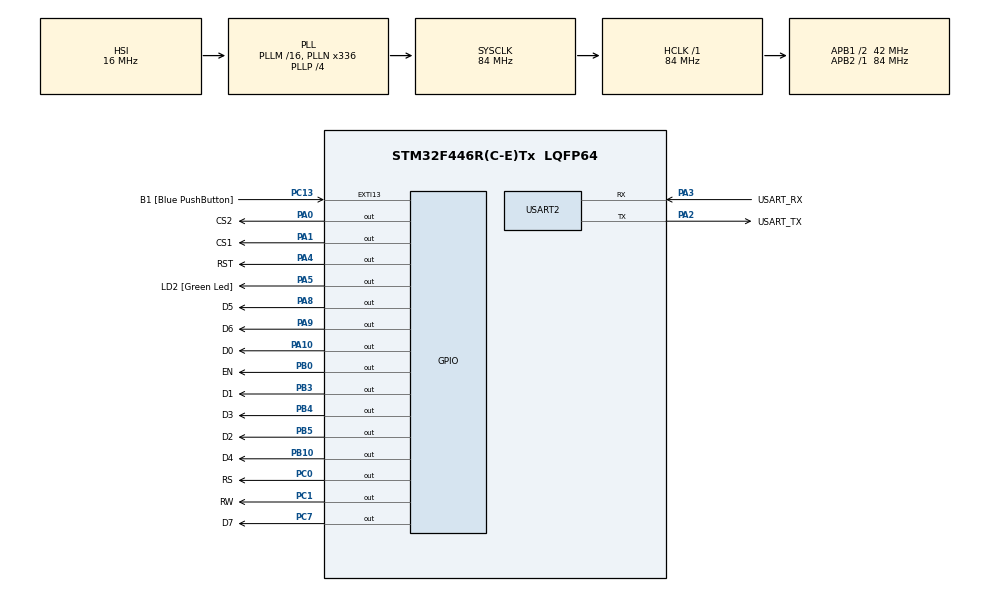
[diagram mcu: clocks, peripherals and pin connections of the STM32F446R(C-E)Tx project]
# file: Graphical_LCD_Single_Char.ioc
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Mcu.Family=STM32F4
Mcu.Name=STM32F446R(C-E)Tx
Mcu.Package=LQFP64
NVIC.PriorityGroup=NVIC_PRIORITYGROUP_0
PA0-WKUP.GPIO_Label=CS2
PA0-WKUP.Signal=GPIO_Output
PA1.GPIO_Label=CS1
PA1.Signal=GPIO_Output
PA10.GPIO_Label=D0
PA10.Signal=GPIO_Output
PA13.GPIO_Label=TMS
PA13.Mode=Serial_Wire
PA13.Signal=SYS_JTMS-SWDIO
PA14.GPIO_Label=TCK
PA14.Mode=Serial_Wire
PA14.Signal=SYS_JTCK-SWCLK
PA2.GPIO_Label=USART_TX
PA2.Mode=Asynchronous
PA2.Signal=USART2_TX
PA3.GPIO_Label=USART_RX
PA3.Mode=Asynchronous
PA3.Signal=USART2_RX
PA4.GPIO_Label=RST
PA4.Signal=GPIO_Output
PA5.GPIO_Label=LD2 [Green Led]
PA5.Signal=GPIO_Output
PA8.GPIO_Label=D5
PA8.Signal=GPIO_Output
PA9.GPIO_Label=D6
PA9.Signal=GPIO_Output
PB0.GPIO_Label=EN
PB0.Signal=GPIO_Output
PB10.GPIO_Label=D4
PB10.Signal=GPIO_Output
PB3.GPIO_Label=D1
PB3.Signal=GPIO_Output
PB4.GPIO_Label=D3
PB4.Signal=GPIO_Output
PB5.GPIO_Label=D2
PB5.Signal=GPIO_Output
PC0.GPIO_Label=RS
PC0.Signal=GPIO_Output
PC1.GPIO_Label=RW
PC1.Signal=GPIO_Output
PC13.GPIO_Label=B1 [Blue PushButton]
PC13.GPIO_ModeDefaultEXTI=GPIO_MODE_IT_FALLING
PC13.Signal=GPXTI13
PC14-OSC32_IN.Mode=LSE-External-Oscillator
PC14-OSC32_IN.Signal=RCC_OSC32_IN
PC15-OSC32_OUT.Mode=LSE-External-Oscillator
PC15-OSC32_OUT.Signal=RCC_OSC32_OUT
PC7.GPIO_Label=D7
PC7.Signal=GPIO_Output
PH0-OSC_IN.Mode=HSE-External-Oscillator
PH0-OSC_IN.Signal=RCC_OSC_IN
PH1-OSC_OUT.Mode=HSE-External-Oscillator
PH1-OSC_OUT.Signal=RCC_OSC_OUT
ProjectManager.HeapSize=0x200
ProjectManager.StackSize=0x400
ProjectManager.TargetToolchain=STM32CubeIDE
RCC.48MHZClocksFreq_Value=84000000
RCC.AHBFreq_Value=84000000
RCC.APB1CLKDivider=RCC_HCLK_DIV2
RCC.APB1Freq_Value=42000000
RCC.APB1TimFreq_Value=84000000
RCC.APB2Freq_Value=84000000
RCC.APB2TimFreq_Value=84000000
RCC.CortexFreq_Value=84000000
RCC.FLatency-AdvancedSettings=FLASH_LATENCY_2
RCC.HCLKFreq_Value=84000000
RCC.HSE_VALUE=8000000
RCC.HSI_VALUE=16000000
RCC.PLLN=336
RCC.PLLP=RCC_PLLP_DIV4
RCC.SYSCLKFreq_VALUE=84000000
RCC.SYSCLKSource=RCC_SYSCLKSOURCE_PLLCLK
RCC.USBFreq_Value=168000000
RCC.VCOOutputFreq_Value=336000000
USART2.VirtualMode=VM_ASYNC
board=NUCLEO-F446RE

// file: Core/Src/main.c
/* USER CODE BEGIN Header */
/**
  ******************************************************************************
  * @file           : main.c
  * @brief          : Main program body
  ******************************************************************************
  * @attention
  *
  * Copyright (c) 2023 STMicroelectronics.
  * All rights reserved.
  *
  * This software is licensed under terms that can be found in the LICENSE file
  * in the root directory of this software component.
  * If no LICENSE file comes with this software, it is provided AS-IS.
  *
  ******************************************************************************
  */
/* USER CODE END Header */
#include "main.h"

/* USER CODE BEGIN Includes */
#include <stdio.h>
#include <string.h>
#include "GLCD_FONT.h"
/* USER CODE END Includes */

/* USER CODE BEGIN PTD */

typedef union{

	struct {

		uint8_t b0:1;
		uint8_t b1:1;
		uint8_t b2:1;
		uint8_t b3:1;
		uint8_t b4:1;
		uint8_t b5:1;
		uint8_t b6:1;
		uint8_t b7:1;
	};

	uint8_t x;
}Typedef_PinConfig;
/* USER CODE END PTD */

UART_HandleTypeDef huart2;

/* USER CODE BEGIN PV */

char data1[] = {0x7F, 0x08, 0x08, 0x08, 0x7F};
char data2[] = {0x7F, 0x49, 0x49, 0x49, 0x41};
char data3[] = {0x7F, 0x40, 0x40, 0x40, 0x40};
char data4[] = {0x7F, 0x40, 0x40, 0x40, 0x40};
char data5[] = {0x3E, 0x41, 0x41, 0x41, 0x3E};

//const char dog[] = {
//		0xff, 0xff, 0xff, 0xff, 0xff, 0xff, 0xff, 0xff, 0xff, 0xff, 0xff, 0xf8, 0x3f, 0xff, 0xff, 0xff,
//		0xff, 0xff, 0xff, 0xff, 0xff, 0xff, 0xff, 0xff, 0xff, 0xff, 0xff, 0xff, 0xff, 0xff, 0xff, 0xff,
//		0xff, 0xff, 0xff, 0xff, 0xff, 0xf0, 0xff, 0xff, 0xff, 0xff, 0xff, 0xff, 0xff, 0xff, 0xff, 0xff,
//		0xff, 0xfc, 0x1f, 0xff, 0xff, 0xff, 0xff, 0xff, 0xff, 0xff, 0xff, 0xff, 0xff, 0xff, 0xff, 0xff,
//		0xff, 0xff, 0xff, 0xff, 0xff, 0xff, 0xff, 0xff, 0xff, 0xff, 0xff, 0xf0, 0xff, 0xff, 0xff, 0xff,
//		0xff, 0xff, 0xff, 0xff, 0xff, 0xff, 0xff, 0xff, 0x1f, 0xff, 0xff, 0xff, 0xff, 0xff, 0xff, 0xff,
//		0xff, 0xff, 0xff, 0xff, 0xff, 0xff, 0xff, 0xff, 0xff, 0xff, 0xff, 0xff, 0xff, 0xff, 0xff, 0xff,
//		0xff, 0xf0, 0xff, 0xff, 0xff, 0xff, 0xff, 0xff, 0xff, 0xff, 0xff, 0xff, 0xff, 0xff, 0xff, 0xff,
//		0xff, 0xff, 0xff, 0xff, 0xff, 0xff, 0xff, 0xff, 0xff, 0xff, 0xff, 0xff, 0xff, 0xff, 0xff, 0xff,
//		0xff, 0xff, 0xff, 0xff, 0xff, 0xff, 0xff, 0xf0, 0xff, 0xff, 0xff, 0xff, 0xff, 0xff, 0xff, 0xff,
//		0xff, 0xff, 0xff, 0xff, 0x9f, 0xff, 0xff, 0xff, 0xff, 0xff, 0xff, 0xff, 0xff, 0xff, 0xff, 0xff,
//		0xff, 0xff, 0xff, 0xff, 0xff, 0xff, 0xff, 0xff, 0xff, 0xff, 0xff, 0xff, 0xff, 0xf0, 0xff, 0xff,
//		0xff, 0xff, 0xff, 0xff, 0xff, 0xff, 0xff, 0xff, 0xfe, 0x7f, 0xcf, 0xff, 0xff, 0xff, 0xff, 0xff,
//		0xff, 0xff, 0xff, 0xff, 0xff, 0xff, 0xff, 0xff, 0xff, 0xff, 0xff, 0xff, 0xff, 0xff, 0xff, 0xff,
//		0xff, 0xff, 0xff, 0xf0, 0xff, 0xff, 0xff, 0xff, 0xff, 0xff, 0xff, 0xff, 0xff, 0xff, 0xfe, 0x1f,
//		0xe7, 0xff, 0xff, 0xff, 0xff, 0xff, 0xff, 0xff, 0xff, 0xff, 0xff, 0xff, 0xff, 0xff, 0xff, 0xff,
//		0xff, 0xff, 0xff, 0xff, 0xff, 0xff, 0xff, 0xff, 0xff, 0xf0, 0xff, 0xff, 0xff, 0xff, 0xff, 0xff,
//		0xff, 0xff, 0xff, 0xff, 0xfe, 0x0f, 0xff, 0xff, 0xff, 0xff, 0xff, 0xff, 0xff, 0xff, 0xff, 0xff,
//		0xff, 0xff, 0xff, 0xff, 0xff, 0xff, 0xff, 0xff, 0xff, 0xff, 0xff, 0xff, 0xff, 0xff, 0xff, 0xf0,
//		0xff, 0xff, 0xff, 0xff, 0xff, 0xff, 0xff, 0xff, 0xff, 0xff, 0xfe, 0x07, 0xff, 0xff, 0xff, 0xff,
//		0xff, 0xff, 0xff, 0xff, 0xff, 0xff, 0xff, 0xff, 0xff, 0xf7, 0xff, 0xff, 0xff, 0xff, 0xff, 0xff,
//		0xff, 0xff, 0xff, 0xff, 0xff, 0xf0, 0xff, 0xff, 0xff, 0xff, 0xff, 0xff, 0xff, 0xff, 0xff, 0xff,
//		0xff, 0x83, 0xff, 0xff, 0xff, 0xff, 0xff, 0xff, 0xff, 0xff, 0xff, 0xff, 0xff, 0xff, 0xff, 0xe2,
//		0xff, 0xff, 0xff, 0xff, 0xff, 0xff, 0xff, 0xff, 0xff, 0xff, 0xff, 0xf0, 0xff, 0xff, 0xff, 0xff,
//		0xff, 0xff, 0xff, 0xff, 0xff, 0xff, 0xff, 0x01, 0xff, 0xff, 0xff, 0xff, 0xff, 0xff, 0xff, 0xff,
//		0xff, 0xff, 0xff, 0xff, 0xff, 0xe0, 0xff, 0xff, 0xff, 0xff, 0xff, 0xff, 0xff, 0xff, 0xff, 0xff,
//		0xff, 0xf0, 0xff, 0xff, 0xff, 0xff, 0xff, 0xff, 0xff, 0xff, 0xff, 0xff, 0xfc, 0x00, 0xff, 0xff,
//		0xff, 0xff, 0xff, 0xff, 0xff, 0xff, 0xff, 0xff, 0xff, 0xff, 0xfe, 0xc0, 0xff, 0xff, 0xff, 0xff,
//		0xff, 0xff, 0xff, 0xff, 0xff, 0xff, 0xff, 0xf0, 0xff, 0xff, 0xff, 0xff, 0xff, 0xff, 0xff, 0xff,
//		0xff, 0xff, 0xfc, 0x00, 0x7f, 0xff, 0xff, 0xff, 0xff, 0xff, 0xff, 0xff, 0xff, 0xff, 0xff, 0xff,
//		0xfd, 0x80, 0xff, 0xff, 0xff, 0xff, 0xff, 0xff, 0xff, 0xff, 0xff, 0xff, 0xff, 0xf0, 0xff, 0xff,
//		0xff, 0xff, 0xff, 0xff, 0xff, 0xff, 0xff, 0xff, 0xfc, 0x00, 0x7f, 0xff, 0xff, 0xff, 0xff, 0xff,
//		0xff, 0xff, 0xff, 0xff, 0xff, 0xff, 0xf9, 0x00, 0xff, 0xff, 0xff, 0xff, 0xff, 0xff, 0xff, 0xff,
//		0xff, 0xff, 0xff, 0xf0, 0xff, 0xff, 0xff, 0xff, 0xff, 0xff, 0xff, 0xff, 0xff, 0xff, 0xfe, 0x0e,
//		0xff, 0xff, 0xff, 0xff, 0xff, 0xff, 0xff, 0xff, 0xff, 0xff, 0xff, 0xff, 0xf8, 0x00, 0xff, 0xff,
//		0xff, 0xff, 0xff, 0xff, 0xff, 0xff, 0xff, 0xff, 0xff, 0xf0, 0xff, 0xff, 0xff, 0xff, 0xff, 0xff,
//		0xff, 0xff, 0xff, 0xff, 0xfe, 0x03, 0xff, 0xff, 0xff, 0xff, 0xff, 0xff, 0xff, 0xff, 0xff, 0xff,
//		0xff, 0xff, 0xf0, 0x01, 0xff, 0xff, 0xff, 0xff, 0xff, 0xff, 0xff, 0xff, 0xff, 0xff, 0xff, 0xf0,
//		0xff, 0xff, 0xff, 0xff, 0xff, 0xff, 0xff, 0xff, 0xff, 0xff, 0xfc, 0x31, 0xff, 0xff, 0xff, 0xff,
//		0xff, 0xff, 0xff, 0xff, 0xff, 0xff, 0xff, 0xff, 0xf1, 0x01, 0xff, 0xff, 0xff, 0xff, 0xff, 0xff,
//		0xff, 0xff, 0xff, 0xff, 0xff, 0xf0, 0xff, 0xff, 0xff, 0xff, 0xff, 0xff, 0xff, 0xff, 0xff, 0xff,
//		0xfe, 0x0f, 0xff, 0xff, 0xff, 0xff, 0xff, 0xff, 0xff, 0xff, 0xff, 0xff, 0xff, 0xff, 0xfe, 0x03,
//		0xff, 0xff, 0xff, 0xff, 0xff, 0xff, 0xff, 0xff, 0xff, 0xff, 0xff, 0xf0, 0xff, 0xff, 0xff, 0xff,
//		0xff, 0xff, 0xff, 0xff, 0xff, 0xff, 0xfe, 0x01, 0xff, 0xff, 0xff, 0xff, 0xff, 0xff, 0xff, 0xff,
//		0xff, 0xff, 0xff, 0xff, 0xfe, 0x03, 0xff, 0xff, 0xff, 0xff, 0xff, 0xff, 0xff, 0xff, 0xff, 0xff,
//		0xff, 0xf0, 0xff, 0xff, 0xff, 0xff, 0xff, 0xff, 0xff, 0xff, 0xff, 0xff, 0xff, 0x01, 0xff, 0xff,
//		0xff, 0xff, 0xff, 0xff, 0xff, 0xff, 0xff, 0xff, 0xff, 0xff, 0xff, 0x8f, 0xff, 0xff, 0xff, 0xff,
//		0xff, 0xff, 0xff, 0xff, 0xff, 0xff, 0xff, 0xf0, 0xff, 0xff, 0xff, 0xff, 0xff, 0xff, 0xff, 0xff,
//		0xff, 0xff, 0xff, 0x0f, 0xff, 0xff, 0xff, 0xff, 0xff, 0xff, 0xff, 0xff, 0xff, 0xff, 0xff, 0xff,
//		0xff, 0xff, 0xff, 0xff, 0xff, 0xff, 0xff, 0xff, 0xff, 0xff, 0xff, 0xff, 0xff, 0xf0, 0xff, 0xff,
//		0xff, 0xff, 0xff, 0xff, 0xff, 0xff, 0xff, 0xff, 0xff, 0x07, 0xff, 0xff, 0xff, 0xff, 0xff, 0xff,
//		0xff, 0xff, 0xff, 0xff, 0xff, 0xff, 0xff, 0xff, 0xff, 0xff, 0xff, 0xff, 0xff, 0xff, 0xff, 0xff,
//		0xff, 0xff, 0xff, 0xf0, 0xff, 0xff, 0xff, 0xff, 0xff, 0xff, 0xff, 0xff, 0xff, 0xff, 0xff, 0x87,
//		0xff, 0xff, 0xff, 0xff, 0xff, 0xff, 0xff, 0xff, 0xff, 0xff, 0xff, 0xff, 0xff, 0xff, 0xff, 0xff,
//		0xff, 0xff, 0xff, 0xff, 0xff, 0xff, 0xff, 0xff, 0xff, 0xf0, 0xff, 0xff, 0xff, 0xff, 0xff, 0xff,
//		0xff, 0xff, 0xff, 0xff, 0xff, 0xff, 0xff, 0xff, 0xff, 0xff, 0xff, 0xff, 0xff, 0xff, 0xff, 0xff,
//		0xff, 0xff, 0xff, 0xff, 0xff, 0xff, 0xff, 0xff, 0xff, 0xff, 0xff, 0xff, 0xff, 0xff, 0xff, 0xf0,
//		0xff, 0xff, 0xff, 0xff, 0xff, 0xff, 0xff, 0xff, 0xff, 0xff, 0xff, 0xff, 0xff, 0xff, 0xff, 0xff,
//		0xff, 0xff, 0xff, 0xff, 0xff, 0xff, 0xff, 0xff, 0xff, 0xff, 0xff, 0xff, 0xff, 0xff, 0xff, 0xff,
//		0xff, 0xff, 0xff, 0xff, 0xff, 0xf0, 0xff, 0xff, 0xff, 0xff, 0xff, 0xff, 0xff, 0xff, 0xff, 0xff,
//		0xff, 0xff, 0xff, 0xff, 0xff, 0xff, 0xff, 0xff, 0xff, 0xff, 0xff, 0xff, 0xff, 0xff, 0xff, 0xff,
//		0xff, 0xff, 0xff, 0xff, 0xff, 0xff, 0xff, 0xff, 0xff, 0xff, 0xff, 0xf0, 0xff, 0xff, 0xff, 0xff,
//		0xff, 0xff, 0xff, 0xff, 0xff, 0xff, 0xff, 0xff, 0xff, 0xff, 0xff, 0xff, 0xff, 0xff, 0xff, 0xff,
//		0xff, 0xff, 0xff, 0xff, 0xff, 0xff, 0xff, 0xff, 0xff, 0xff, 0xff, 0xff, 0xff, 0xff, 0xff, 0xff,
//		0xff, 0xf0, 0xff, 0xff, 0xff, 0xff, 0xff, 0xff, 0xff, 0xff, 0xff, 0xff, 0xff, 0xff, 0xff, 0xff,
//		0xff, 0xff, 0xff, 0xff, 0xff, 0xff, 0xff, 0xff, 0xff, 0xff, 0xff, 0xff, 0xff, 0xff, 0xff, 0xff,
//		0xff, 0xff, 0xff, 0xff, 0xff, 0xff, 0xff, 0xf0, 0xff, 0xff, 0xff, 0xff, 0xff, 0xff, 0xff, 0xff,
//		0xff, 0xff, 0xff, 0xff, 0xff, 0xff, 0xff, 0xff, 0xff, 0xff, 0xff, 0xff, 0xff, 0xff, 0xff, 0xff,
//		0xff, 0xff, 0xff, 0xff, 0xff, 0xff, 0xff, 0xff, 0xff, 0xff, 0xff, 0xff, 0xff, 0xf0, 0xff, 0xff,
//		0xff, 0xff, 0xff, 0xff, 0xff, 0xff, 0xff, 0xff, 0xff, 0xff, 0xff, 0xff, 0xff, 0xff, 0xff, 0xff,
//		0xff, 0xff, 0xff, 0xff, 0xff, 0xff, 0xff, 0xff, 0xff, 0xff, 0xff, 0xff, 0xff, 0xff, 0xff, 0xff,
//		0xff, 0xff, 0xff, 0xf0, 0xff, 0xff, 0xff, 0xff, 0xff, 0xff, 0xff, 0xff, 0xff, 0xff, 0xff, 0xff,
//		0xff, 0xff, 0xff, 0xff, 0xff, 0xff, 0xff, 0xff, 0xff, 0xff, 0xff, 0xff, 0xff, 0xff, 0xff, 0xff,
//		0xff, 0xff, 0xff, 0xff, 0xff, 0xff, 0xff, 0xff, 0xff, 0xf0, 0xff, 0xff, 0xff, 0xff, 0xff, 0xff,
//		0xff, 0xff, 0xff, 0xff, 0xff, 0xff, 0xff, 0xff, 0xff, 0xff, 0xff, 0xff, 0xff, 0xff, 0xff, 0xff,
//		0xff, 0xff, 0xff, 0xff, 0xff, 0xff, 0xff, 0xff, 0xff, 0xff, 0xff, 0xff, 0xff, 0xff, 0xff, 0xf0,
//		0xff, 0xff, 0xff, 0xff, 0xff, 0xff, 0xff, 0xff, 0xff, 0xff, 0xff, 0xff, 0xff, 0xff, 0xff, 0xff,
//		0xff, 0xff, 0xff, 0xff, 0xff, 0xff, 0xff, 0xff, 0xff, 0xff, 0xff, 0xff, 0xff, 0xff, 0xff, 0xff,
//		0xff, 0xff, 0xff, 0xff, 0xff, 0xf0, 0xff, 0xff, 0xff, 0xff, 0xff, 0xff, 0xff, 0xff, 0xff, 0xff,
//		0xff, 0xff, 0xff, 0xff, 0xff, 0xff, 0xff, 0xff, 0xff, 0xff, 0xff, 0xff, 0xff, 0xff, 0xff, 0xff,
//		0xff, 0xff, 0xff, 0xff, 0xff, 0xff, 0xff, 0xff, 0xff, 0xff, 0xff, 0xf0, 0xff, 0xff, 0xff, 0xff,
//		0xff, 0xff, 0xff, 0xff, 0xff, 0xff, 0xff, 0xff, 0xff, 0xff, 0xff, 0xff, 0xff, 0xff, 0xff, 0xff,
//		0xff, 0xff, 0xff, 0xff, 0xff, 0xff, 0xff, 0xff, 0xff, 0xff, 0xff, 0xff, 0xff, 0xff, 0xff, 0xff,
//		0xff, 0xf0, 0xff, 0xff, 0xff, 0xff, 0xff, 0xff, 0xff, 0xff, 0xff, 0xff, 0xff, 0xff, 0xff, 0xff,
//		0xff, 0xff, 0xff, 0xff, 0xff, 0xff, 0xff, 0xff, 0xff, 0xff, 0xff, 0xff, 0xff, 0xff, 0xff, 0xff,
//		0xff, 0xff, 0xff, 0xff, 0xff, 0xff, 0xff, 0xf0, 0xff, 0xff, 0xff, 0xff, 0xff, 0xff, 0xff, 0xff,
//		0xff, 0xff, 0xff, 0xff, 0xff, 0xff, 0xff, 0xff, 0xff, 0xff, 0xff, 0xff, 0xff, 0xff, 0xff, 0xff,
//		0xff, 0xff, 0xff, 0xff, 0xff, 0xff, 0xff, 0xff, 0xff, 0xff, 0xff, 0xff, 0xff, 0xf0, 0xff, 0xff,
//		0xff, 0xff, 0xff, 0xff, 0xff, 0xff, 0xff, 0xff, 0xff, 0xff, 0xff, 0xff, 0xff, 0xff, 0xff, 0xff,
//		0xff, 0xff, 0xff, 0xff, 0xff, 0xff, 0xff, 0xff, 0xff, 0xff, 0xff, 0xff, 0xff, 0xff, 0xff, 0xff,
//		0xff, 0xff, 0xff, 0xf0, 0xff, 0xff, 0xff, 0xff, 0xff, 0xff, 0xff, 0xff, 0xff, 0xff, 0xff, 0xff,
//		0xff, 0xff, 0xff, 0xff, 0xff, 0xff, 0xff, 0xff, 0xff, 0xff, 0xff, 0xff, 0xff, 0xff, 0xff, 0xff,
//		0xff, 0xff, 0xff, 0xff, 0xff, 0xff, 0xff, 0xff, 0xff, 0xf0, 0xff, 0xff, 0xff, 0xff, 0xff, 0xff,
//		0xff, 0xff, 0xff, 0xff, 0xff, 0xff, 0xff, 0xff, 0xff, 0xff, 0xff, 0xff, 0xff, 0xff, 0xff, 0xff,
//		0xff, 0xff, 0xff, 0xff, 0xff, 0xff, 0xff, 0xff, 0xff, 0xff, 0xff, 0xff, 0xff, 0xff, 0xff, 0xf0,
//		0xff, 0xff, 0xff, 0xff, 0xff, 0xff, 0xff, 0xff, 0xff, 0xff, 0xff, 0xff, 0xff, 0xff, 0xff, 0xff,
//		0xff, 0xff, 0xff, 0xff, 0xff, 0xff, 0xff, 0xff, 0xff, 0xff, 0xff, 0xff, 0xff, 0xff, 0xff, 0xff,
//		0xff, 0xff, 0xff, 0xff, 0xff, 0xf0, 0xff, 0xff, 0xff, 0xff, 0xff, 0xff, 0xff, 0xff, 0xff, 0xff,
//		0xff, 0xff, 0xff, 0xff, 0xff, 0xff, 0xff, 0xff, 0xff, 0xff, 0xff, 0xff, 0xff, 0xff, 0xff, 0xff,
//		0xff, 0xff, 0xff, 0xff, 0xff, 0xff, 0xff, 0xff, 0xff, 0xff, 0xff, 0xf0, 0xff, 0xff, 0xff, 0xff,
//		0xff, 0xff, 0xff, 0xff, 0xff, 0xff, 0xff, 0xff, 0xff, 0xff, 0xff, 0xff, 0xff, 0xff, 0xff, 0xff,
//		0xff, 0xff, 0xff, 0xff, 0xff, 0xff, 0xff, 0xff, 0xff, 0xff, 0xff, 0xff, 0xff, 0xff, 0xff, 0xff,
//		0xff, 0xf0, 0xff, 0xff, 0xff, 0xff, 0xff, 0xff, 0xff, 0xff, 0xff, 0xff, 0xff, 0xff, 0xff, 0xff,
//		0xff, 0xff, 0xff, 0xff, 0xff, 0xff, 0xff, 0xff, 0xff, 0xff, 0xff, 0xff, 0xff, 0xff, 0xff, 0xff,
//		0xff, 0xff, 0xff, 0xff, 0xff, 0xff, 0xff, 0xf0, 0xff, 0xff, 0xff, 0xff, 0xff, 0xff, 0xff, 0xff,
//		0xff, 0xff, 0xff, 0xff, 0xff, 0xff, 0xff, 0xff, 0xff, 0xff, 0xff, 0xff, 0xff, 0xff, 0xff, 0xff,
//		0xff, 0xff, 0xff, 0xff, 0xff, 0xff, 0xff, 0xff, 0xff, 0xff, 0xff, 0xff, 0xff, 0xf0, 0xff, 0xff,
//		0xff, 0xff, 0xff, 0xff, 0xff, 0xff, 0xff, 0xff, 0xff, 0xff, 0xff, 0xff, 0xff, 0xff, 0xff, 0xff,
//		0xff, 0xff, 0xff, 0xff, 0xff, 0xff, 0xff, 0xff, 0xff, 0xff, 0xff, 0xff, 0xff, 0xff, 0xff, 0xff,
//		0xff, 0xff, 0xff, 0xf0, 0xff, 0xff, 0xff, 0xff, 0xff, 0xff, 0xff, 0xff, 0xff, 0xff, 0xff, 0xff,
//		0xff, 0xff, 0xff, 0xff, 0xff, 0xff, 0xff, 0xff, 0xff, 0xff, 0xff, 0xff, 0xff, 0xff, 0xff, 0xff,
//		0xff, 0xff, 0xff, 0xff, 0xff, 0xff, 0xff, 0xff, 0xff, 0xf0, 0xff, 0xff, 0xff, 0xff, 0xff, 0xff,
//		0xff, 0xff, 0xff, 0xff, 0xff, 0xff, 0xff, 0xff, 0xf8, 0x7f, 0xff, 0xff, 0xff, 0xff, 0xff, 0xff,
//		0xff, 0xff, 0xff, 0xff, 0xff, 0xff, 0xff, 0xff, 0xff, 0xff, 0xff, 0xff, 0xff, 0xff, 0xff, 0xf0,
//		0xff, 0xff, 0xff, 0xff, 0xff, 0xff, 0xff, 0xff, 0xff, 0xff, 0xff, 0xff, 0xff, 0xff, 0xc0, 0x3f,
//		0xff, 0xff, 0xff, 0xff, 0xff, 0xff, 0xff, 0xff, 0xff, 0xff, 0xff, 0xff, 0xff, 0xff, 0xff, 0xff,
//		0xff, 0xff, 0xff, 0xff, 0xff, 0xf0, 0xff, 0xff, 0xff, 0xff, 0xff, 0xff, 0xff, 0xff, 0xff, 0xff,
//		0xff, 0xff, 0xff, 0xff, 0x00, 0x07, 0xff, 0xff, 0xff, 0xff, 0xff, 0xff, 0xff, 0xff, 0xff, 0xff,
//		0xff, 0xff, 0xff, 0xff, 0xff, 0xff, 0xff, 0xff, 0xff, 0xff, 0xff, 0xf0, 0xff, 0xff, 0xff, 0xff,
//		0xff, 0xff, 0xff, 0xff, 0xff, 0xff, 0xff, 0xff, 0xff, 0xfc, 0x00, 0x83, 0xff, 0xff, 0xff, 0xff,
//		0xff, 0xe0, 0x7f, 0xff, 0xff, 0xff, 0xff, 0xff, 0xff, 0xff, 0xff, 0xff, 0xff, 0xff, 0xff, 0xff,
//		0xff, 0xf0, 0xff, 0xff, 0xff, 0xff, 0xff, 0xff, 0xff, 0xff, 0xff, 0xff, 0xff, 0xff, 0xff, 0xf8,
//		0x00, 0x83, 0xff, 0xff, 0xff, 0xff, 0xff, 0x80, 0x1f, 0xff, 0xff, 0xff, 0xff, 0xff, 0xff, 0xff,
//		0xff, 0xff, 0xff, 0xff, 0xff, 0xff, 0xff, 0xf0, 0xff, 0xff, 0xff, 0xff, 0xff, 0xff, 0xff, 0xff,
//		0xff, 0xff, 0xff, 0xff, 0xff, 0xf0, 0x00, 0x01, 0xff, 0xff, 0xff, 0xff, 0xff, 0x0e, 0x0f, 0xff,
//		0xff, 0xff, 0xff, 0xff, 0xff, 0xff, 0xff, 0xff, 0xff, 0xff, 0xff, 0xff, 0xff, 0xf0, 0xff, 0xff,
//		0xff, 0xff, 0xff, 0xff, 0xff, 0xff, 0xff, 0xff, 0xff, 0xfb, 0x1f, 0x80, 0x00, 0x00, 0xff, 0xff,
//		0xff, 0xff, 0xfe, 0x07, 0x47, 0xff, 0xff, 0xff, 0xff, 0xff, 0xff, 0xff, 0xff, 0xff, 0xff, 0xff,
//		0xff, 0xff, 0xff, 0xf0, 0xff, 0xff, 0xff, 0xff, 0xff, 0xff, 0xff, 0xff, 0xff, 0xff, 0xff, 0xf9,
//		0x00, 0x00, 0x00, 0x00, 0xff, 0xff, 0xff, 0xff, 0xfe, 0x03, 0x03, 0xff, 0xff, 0xff, 0xff, 0xff,
//		0xff, 0xff, 0xff, 0xff, 0xff, 0xff, 0xff, 0xff, 0xff, 0xf0, 0xff, 0xff, 0xff, 0xff, 0xff, 0xff,
//		0xff, 0xff, 0xff, 0xff, 0xff, 0x9c, 0x00, 0x60, 0x00, 0x00, 0xff, 0xff, 0xff, 0xff, 0xff, 0x00,
//		0x03, 0xff, 0xff, 0xff, 0xff, 0xff, 0xff, 0xff, 0xff, 0xff, 0xff, 0xff, 0xff, 0xff, 0xff, 0xf0,
//		0xff, 0xff, 0xff, 0xff, 0xff, 0xff, 0xff, 0xff, 0xff, 0xff, 0xff, 0x10, 0x00, 0xf8, 0x00, 0x00,
//		0xff, 0xff, 0xff, 0xff, 0xfa, 0x00, 0x25, 0xff, 0xff, 0xff, 0xff, 0xff, 0xff, 0xff, 0xff, 0xff,
//		0xff, 0xff, 0xff, 0xff, 0xff, 0xf0, 0xff, 0xff, 0xff, 0xff, 0xff, 0xff, 0xff, 0xff, 0xff, 0xff,
//		0xff, 0x78, 0x00, 0x7c, 0x00, 0x01, 0xff, 0xff, 0xff, 0xff, 0xfe, 0x00, 0x05, 0xff, 0xff, 0xff,
//		0xff, 0xff, 0xff, 0xff, 0xff, 0xff, 0xff, 0xff, 0xff, 0xff, 0xff, 0xf0, 0xff, 0xff, 0xff, 0xff,
//		0xff, 0xff, 0xff, 0xff, 0xff, 0xff, 0xff, 0xc0, 0x00, 0x7f, 0x00, 0x03, 0xff, 0xff, 0xff, 0xff,
//		0xfc, 0x20, 0x4f, 0xff, 0xff, 0xff, 0xff, 0xff, 0xff, 0xff, 0xff, 0xff, 0xff, 0xff, 0xff, 0xff,
//		0xff, 0xf0, 0xff, 0xff, 0xff, 0xff, 0xff, 0xff, 0xff, 0xff, 0xff, 0xff, 0xff, 0x00, 0x08, 0x7f,
//		0x80, 0x47, 0xff, 0xff, 0xff, 0xff, 0xfc, 0x01, 0x1f, 0xff, 0xff, 0xff, 0xff, 0xff, 0xff, 0xff,
//		0xff, 0xff, 0xff, 0xff, 0xff, 0xff, 0xff, 0xf0, 0xff, 0xff, 0xff, 0xff, 0xff, 0xff, 0xff, 0xff,
//		0xff, 0xff, 0xff, 0x1f, 0xff, 0x3f, 0xff, 0xff, 0xff, 0xff, 0xff, 0xff, 0xff, 0x80, 0x3f, 0xff,
//		0xff, 0xff, 0xff, 0xff, 0xff, 0xff, 0xff, 0xff, 0xff, 0xff, 0xff, 0xff, 0xff, 0xf0, 0xff, 0xff,
//		0xff, 0xff, 0xff, 0xff, 0xff, 0xff, 0xff, 0xff, 0xff, 0xff, 0xff, 0x1f, 0xff, 0xff, 0xff, 0xff,
//		0xff, 0xff, 0xff, 0xd0, 0xff, 0xff, 0xff, 0xff, 0xff, 0xff, 0xff, 0xff, 0xff, 0xff, 0xff, 0xff,
//		0xff, 0xff, 0xff, 0xf0, 0xff, 0xff, 0xff, 0xff, 0xff, 0xff, 0xff, 0xff, 0xff, 0xff, 0xff, 0xff,
//		0xff, 0x8f, 0xff, 0xff, 0xff, 0xff, 0xff, 0xff, 0xff, 0xc1, 0xff, 0xff, 0xff, 0xff, 0xff, 0xff,
//		0xff, 0xff, 0xff, 0xff, 0xff, 0xff, 0xff, 0xff, 0xff, 0xf0, 0xff, 0xff, 0xff, 0xff, 0xff, 0xff,
//		0xff, 0xff, 0xff, 0xff, 0xff, 0xff, 0xfe, 0x87, 0xff, 0xff, 0xff, 0xff, 0xff, 0xff, 0xff, 0xff,
//		0xff, 0xff, 0xff, 0xff, 0xff, 0xff, 0xff, 0xff, 0xff, 0xff, 0xff, 0xff, 0xff, 0xff, 0xff, 0xf0,
//		0xff, 0xff, 0xff, 0xff, 0xff, 0xff, 0xff, 0xff, 0xff, 0xff, 0xff, 0xff, 0xff, 0x83, 0xff, 0xff,
//		0xff, 0xff, 0xff, 0xff, 0xff, 0xff, 0xff, 0xff, 0xff, 0xff, 0xff, 0xff, 0xff, 0xff, 0xff, 0xff,
//		0xff, 0xff, 0xff, 0xff, 0xff, 0xf0, 0xff, 0xff, 0xff, 0xff, 0xff, 0xff, 0xff, 0xff, 0xff, 0xff,
//		0xff, 0xff, 0xff, 0xc3, 0xff, 0xff, 0xff, 0xff, 0xff, 0xff, 0xff, 0xff, 0xff, 0xff, 0xff, 0xff,
//		0xff, 0xff, 0xff, 0xff, 0xff, 0xff, 0xff, 0xff, 0xff, 0xff, 0xff, 0xf0, 0xff, 0xff, 0xff, 0xff,
//		0xff, 0xff, 0xff, 0xff, 0xff, 0xff, 0xff, 0xff, 0xff, 0xc1, 0xff, 0xff, 0xff, 0xff, 0xff, 0xff,
//		0xff, 0xff, 0xff, 0xff, 0xff, 0xff, 0xff, 0xff, 0xff, 0xff, 0xff, 0xff, 0xff, 0xff, 0xff, 0xff,
//		0xff, 0xf0, 0xff, 0xff, 0xff, 0xff, 0xff, 0xff, 0xff, 0xff, 0xff, 0xff, 0xff, 0xff, 0xff, 0xc0,
//		0x7f, 0xff, 0xff, 0xff, 0xff, 0xff, 0xff, 0xff, 0xff, 0xff, 0xff, 0xff, 0xff, 0xff, 0xff, 0xff,
//		0xff, 0xff, 0xff, 0xff, 0xff, 0xff, 0xff, 0xf0, 0xff, 0xff, 0xff, 0xff, 0xff, 0xff, 0xff, 0xff,
//		0xff, 0xff, 0xff, 0xff, 0xff, 0xc0, 0x3f, 0xff, 0xff, 0xff, 0xff, 0xff, 0xff, 0xff, 0xff, 0xff,
//		0xff, 0xff, 0xff, 0xff, 0xff, 0xff, 0xff, 0xff, 0xff, 0xff, 0xff, 0xff, 0xff, 0xf0, 0xff, 0xff,
//		0xff, 0xff, 0xff, 0xff, 0xff, 0xff, 0xff, 0xff, 0xff, 0xff, 0xff, 0xe0, 0x7f, 0xff, 0xff, 0xff,
//		0xff, 0xff, 0xff, 0xff, 0xff, 0xff, 0xff, 0xff, 0xff, 0xff, 0xff, 0xff, 0xff, 0xff, 0xff, 0xff,
//		0xff, 0xff, 0xff, 0xf0, 0xff, 0xff, 0xff, 0xff, 0xff, 0xff, 0xff, 0xff, 0xff, 0xfb, 0xff, 0xff,
//		0xff, 0xf0, 0x7f, 0xff, 0xff, 0xff, 0xff, 0xff, 0xff, 0xff, 0xff, 0xff, 0xff, 0xff, 0xff, 0xff,
//		0xff, 0xff, 0xff, 0xff, 0xff, 0xff, 0xff, 0xff, 0xff, 0xf0, 0xff, 0xff, 0xff, 0xff, 0xff, 0xff,
//		0xff, 0xff, 0xff, 0xe7, 0xff, 0xff, 0xff, 0xff, 0xff, 0xff, 0xff, 0xff, 0xff, 0xff, 0xff, 0xff,
//		0xff, 0xff, 0xff, 0xff, 0xff, 0xff, 0xff, 0xff, 0xff, 0xff, 0xff, 0xff, 0xff, 0xff, 0xff, 0xf0,
//		0xff, 0xff, 0xff, 0xff, 0xff, 0xff, 0xff, 0xff, 0xff, 0x87, 0xff, 0xff, 0xff, 0xff, 0xff, 0xff,
//		0xff, 0xff, 0xff, 0xff, 0xff, 0xff, 0xff, 0xff, 0xff, 0xff, 0xff, 0xff, 0xff, 0xff, 0xff, 0xff,
//		0xff, 0xff, 0xff, 0xff, 0xff, 0xf0, 0xff, 0xff, 0xff, 0xff, 0xff, 0xff, 0xff, 0xff, 0xfe, 0x1f,
//		0xff, 0xff, 0xff, 0xff, 0xff, 0xff, 0xff, 0xff, 0xff, 0xff, 0xff, 0xff, 0xff, 0xff, 0xff, 0xff,
//		0xff, 0xff, 0xff, 0xff, 0xff, 0xff, 0xff, 0xff, 0xff, 0xff, 0xff, 0xf0, 0xff, 0xff, 0xff, 0xff,
//		0xff, 0xff, 0xff, 0xff, 0xf8, 0x3f, 0xff, 0xff, 0xff, 0xff, 0xff, 0xff, 0xff, 0xff, 0xff, 0xff,
//		0xff, 0xff, 0xff, 0xff, 0xff, 0xff, 0xff, 0xff, 0xff, 0xff, 0xff, 0xff, 0xff, 0xff, 0xff, 0xff,
//		0xff, 0xf0, 0xff, 0xff, 0xff, 0xff, 0xff, 0xff, 0xff, 0xff, 0xf0, 0xff, 0xff, 0xff, 0xff, 0xff,
//		0xff, 0xff, 0xff, 0xff, 0xff, 0xff, 0xff, 0xff, 0xff, 0xff, 0xff, 0xff, 0xff, 0xff, 0xff, 0xff,
//		0xff, 0xff, 0xff, 0xff, 0xff, 0xff, 0xff, 0xf0, 0xff, 0xff, 0xff, 0xff, 0xff, 0xff, 0xff, 0xff,
//		0xff, 0xff, 0xff, 0xff, 0xff, 0xff, 0xff, 0xff, 0xff, 0xff, 0xff, 0xff, 0xff, 0xff, 0xff, 0xff,
//		0xff, 0xff, 0xff, 0xff, 0xff, 0xff, 0xff, 0xff, 0xff, 0xff, 0xff, 0xff, 0xff, 0xf0, 0xff, 0xff,
//		0xff, 0xff, 0xff, 0xff, 0xff, 0xff, 0xff, 0xff, 0xff, 0xff, 0xff, 0xff, 0xff, 0xff, 0xff, 0xff,
//		0xff, 0xff, 0xff, 0xff, 0xff, 0xff, 0xff, 0xff, 0xff, 0xff, 0xff, 0xff, 0xff, 0xff, 0xff, 0xff,
//		0xff, 0xff, 0xff, 0xf0, 0xff, 0xff, 0xff, 0xff, 0xff, 0xff, 0xff, 0xff, 0xff, 0xff, 0xff, 0xff,
//		0xff, 0xff, 0xff, 0xff, 0xff, 0xff, 0xff, 0xff, 0xff, 0xff, 0xff, 0xff, 0xff, 0xff, 0xff, 0xff,
//		0xff, 0xff, 0xff, 0xff, 0xff, 0xff, 0xff, 0xff, 0xff, 0xf0, 0xff, 0xff, 0xff, 0xff, 0xff, 0xff,
//		0xff, 0xff, 0xff, 0xff, 0xff, 0xff, 0xff, 0xff, 0xff, 0xff, 0xff, 0xff, 0xff, 0xff, 0xff, 0xff,
//		0xff, 0xff, 0xff, 0xff, 0xff, 0xff, 0xff, 0xff, 0xff, 0xff, 0xff, 0xff, 0xff, 0xff, 0xff, 0xf0,
//		0xff, 0xff, 0xff, 0xff, 0xff, 0xff, 0xff, 0xff, 0xff, 0xff, 0xff, 0xff, 0xff, 0xff, 0xff, 0xff,
//		0xff, 0xff, 0xff, 0xff, 0xff, 0xff, 0xff, 0xff, 0xff, 0xff, 0xff, 0xff, 0xff, 0xff, 0xff, 0xff,
//		0xff, 0xff, 0xff, 0xff, 0xff, 0xf0, 0xff, 0xff, 0xff, 0xff, 0xff, 0xff, 0xff, 0xff, 0xff, 0xff,
//		0xff, 0xff, 0xff, 0xff, 0xff, 0xff, 0xff, 0xf0, 0xff, 0xff, 0xff, 0xff, 0xff, 0xff, 0xff, 0xff,
//		0xff, 0xff, 0xff, 0xff, 0xff, 0xff, 0xff, 0xff, 0xff, 0xff, 0xff, 0xf0, 0xff, 0xff, 0xff, 0xff,
//		0xff, 0xff, 0xff, 0xff, 0xff, 0xff, 0xff, 0xff, 0xff, 0xff, 0xff, 0xff, 0xff, 0x80, 0x00, 0x3f,
//		0xff, 0xff, 0xff, 0xff, 0xff, 0xff, 0xff, 0xff, 0xff, 0xff, 0xff, 0xff, 0xff, 0xff, 0xff, 0xff,
//		0xff, 0xf0, 0xff, 0xff, 0xff, 0xff, 0xff, 0xff, 0xff, 0xff, 0xff, 0xff, 0xff, 0xff, 0xff, 0xff,
//		0xff, 0xff, 0xff, 0x00, 0x00, 0x0f, 0xff, 0xff, 0xff, 0xff, 0xff, 0xff, 0xff, 0xff, 0xff, 0xff,
//		0xff, 0xff, 0xff, 0xff, 0xff, 0xff, 0xff, 0xf0, 0xff, 0xff, 0xff, 0xff, 0xff, 0xff, 0xff, 0xff,
//		0xff, 0xff, 0xff, 0xff, 0xff, 0xff, 0xff, 0xff, 0xfc, 0x00, 0xff, 0xff, 0xff, 0xff, 0xff, 0xff,
//		0xff, 0xff, 0xff, 0xff, 0xff, 0xff, 0xff, 0xff, 0xff, 0xff, 0xff, 0xff, 0xff, 0xf0, 0xff, 0xff,
//		0xff, 0xff, 0xff, 0xff, 0xff, 0xff, 0xff, 0xff, 0xff, 0xff, 0xff, 0xff, 0xff, 0xff, 0xf8, 0x01,
//		0xff, 0xfb, 0xff, 0xff, 0xff, 0xff, 0xff, 0xff, 0xff, 0xff, 0xff, 0xff, 0xff, 0xff, 0xff, 0xff,
//		0xff, 0xff, 0xff, 0xf0, 0xff, 0xff, 0xff, 0xff, 0xff, 0xff, 0xff, 0xff, 0xff, 0xff, 0xff, 0xff,
//		0xff, 0xff, 0xff, 0xff, 0xf8, 0x03, 0xff, 0xff, 0xff, 0xff, 0xff, 0xff, 0xff, 0xff, 0xff, 0xff,
//		0xff, 0xff, 0xff, 0xff, 0xff, 0xff, 0xff, 0xff, 0xff, 0xf0, 0xff, 0xff, 0xff, 0xff, 0xff, 0xff,
//		0xff, 0xff, 0xff, 0xff, 0xff, 0xff, 0xff, 0xff, 0xff, 0xff, 0xf0, 0x01, 0xff, 0xfe, 0x7f, 0xff,
//		0xff, 0xff, 0xff, 0xff, 0xff, 0xff, 0xff, 0xff, 0xff, 0xff, 0xff, 0xff, 0xff, 0xff, 0xff, 0xf0,
//		0xff, 0xff, 0xff, 0xff, 0xff, 0xff, 0xff, 0xff, 0xff, 0xff, 0xff, 0xff, 0xff, 0xff, 0xff, 0xff,
//		0xe0, 0x00, 0x01, 0xfc, 0x7f, 0xff, 0xff, 0xff, 0xff, 0xff, 0xff, 0xff, 0xff, 0xff, 0xff, 0xff,
//		0xff, 0xff, 0xff, 0xff, 0xff, 0xf0, 0xff, 0xff, 0xff, 0xff, 0xff, 0xff, 0xff, 0xff, 0xff, 0xff,
//		0xff, 0xff, 0xff, 0xff, 0xff, 0xff, 0xe0, 0x00, 0x00, 0x18, 0x7f, 0xff, 0xff, 0xff, 0xff, 0xff,
//		0xff, 0xff, 0xff, 0xff, 0xff, 0xff, 0xff, 0xff, 0xff, 0xff, 0xff, 0xf0, 0xff, 0xff, 0xff, 0xff,
//		0xff, 0xff, 0xff, 0xff, 0xff, 0xff, 0xff, 0xff, 0xff, 0xff, 0xff, 0xff, 0xc0, 0x00, 0x00, 0x00,
//		0x7f, 0xff, 0xff, 0xff, 0xff, 0xff, 0xff, 0xff, 0xff, 0xff, 0xff, 0xff, 0xff, 0xff, 0xff, 0xff,
//		0xff, 0xf0, 0xff, 0xff, 0xff, 0xff, 0xff, 0xff, 0xff, 0xff, 0xff, 0xff, 0xff, 0xf8, 0x7f, 0xff,
//		0xff, 0xff, 0xe0, 0x00, 0x00, 0x00, 0x7f, 0xff, 0xff, 0xff, 0xff, 0xff, 0xff, 0xff, 0xff, 0xff,
//		0xff, 0xff, 0xff, 0xff, 0xff, 0xff, 0xff, 0xf0, 0xff, 0xff, 0xff, 0xff, 0xff, 0xff, 0xff, 0xff,
//		0xff, 0xff, 0xff, 0xc0, 0x3f, 0xff, 0xff, 0xff, 0xc0, 0x00, 0x00, 0x00, 0x7f, 0xff, 0xff, 0xff,
//		0xff, 0xff, 0xff, 0xff, 0xff, 0xff, 0xff, 0xff, 0xff, 0xff, 0xff, 0xff, 0xff, 0xf0, 0xff, 0xff,
//		0xff, 0xff, 0xff, 0xff, 0xff, 0xff, 0xff, 0xff, 0xff, 0x00, 0x1f, 0xff, 0xff, 0xff, 0x80, 0x00,
//		0x00, 0x00, 0x7f, 0xff, 0xff, 0xff, 0xff, 0xff, 0xff, 0xff, 0xff, 0xff, 0xff, 0xff, 0xff, 0xff,
//		0xff, 0xff, 0xff, 0xf0, 0xff, 0xff, 0xff, 0xff, 0xff, 0xff, 0xff, 0xff, 0xff, 0xff, 0xfe, 0x00,
//		0x0f, 0xff, 0xff, 0xdf, 0x00, 0x00, 0x00, 0x00, 0x7f, 0xff, 0xff, 0xff, 0xff, 0xff, 0xff, 0xff,
//		0xff, 0xff, 0xff, 0xff, 0xff, 0xff, 0xff, 0xff, 0xff, 0xf0, 0xff, 0xff, 0xff, 0xff, 0xff, 0xff,
//		0xff, 0xff, 0xff, 0xff, 0xfc, 0x00, 0x07, 0xe3, 0xff, 0xff, 0xc0, 0x00, 0x00, 0x00, 0x7f, 0xff,
//		0xff, 0xff, 0xff, 0xff, 0xff, 0xff, 0xff, 0xff, 0xff, 0xff, 0xff, 0xff, 0xff, 0xff, 0xff, 0xf0,
//		0xff, 0xff, 0xff, 0xff, 0xff, 0xff, 0xff, 0xff, 0xff, 0xff, 0xfc, 0x00, 0x07, 0xc1, 0xff, 0xff,
//		0x00, 0x00, 0x00, 0x01, 0xff, 0xff, 0xff, 0xff, 0xff, 0xff, 0xff, 0xff, 0xff, 0xff, 0xff, 0xff,
//		0xff, 0xff, 0xff, 0xff, 0xff, 0xf0, 0xff, 0xff, 0xff, 0xff, 0xff, 0xff, 0xff, 0xff, 0xff, 0xff,
//		0xfe, 0x00, 0x07, 0xe1, 0xff, 0xef, 0x00, 0x00, 0x00, 0x4e, 0xff, 0xff, 0xff, 0xff, 0xff, 0xff,
//		0xff, 0xff, 0xff, 0xff, 0xff, 0xff, 0xff, 0xff, 0xff, 0xff, 0xff, 0xf0, 0xff, 0xff, 0xff, 0xff,
//		0xff, 0xff, 0xff, 0xff, 0xff, 0xff, 0xfe, 0x00, 0x03, 0xe0, 0x7f, 0xc4, 0x00, 0x00, 0x00, 0x78,
//		0xff, 0xff, 0xff, 0xff, 0xff, 0xff, 0xff, 0xff, 0xff, 0xff, 0xff, 0xff, 0xff, 0xff, 0xff, 0xff,
//		0xff, 0xf0, 0xff, 0xff, 0xff, 0xff, 0xff, 0xff, 0xff, 0xff, 0xff, 0xff, 0xff, 0x00, 0x01, 0xe0,
//		0x7f, 0xf8, 0x00, 0x00, 0x00, 0x01, 0xff, 0xff, 0xff, 0xff, 0xff, 0xff, 0xff, 0xff, 0xfe, 0xff,
//		0xff, 0xff, 0xff, 0xff, 0xff, 0xff, 0xff, 0xf0, 0xff, 0xff, 0xff, 0xff, 0xff, 0xff, 0xff, 0xff,
//		0xff, 0xff, 0xff, 0x00, 0x01, 0xe0, 0x3f, 0xf8, 0x00, 0x00, 0x00, 0x03, 0xff, 0xff, 0xff, 0xff,
//		0xff, 0xff, 0xff, 0xff, 0xf8, 0x7f, 0xff, 0xff, 0xff, 0xff, 0xff, 0xff, 0xff, 0xf0, 0xff, 0xff,
//		0xff, 0xff, 0xff, 0xff, 0xff, 0xff, 0xff, 0xff, 0xff, 0x00, 0x01, 0xe0, 0x1f, 0xf8, 0x00, 0x00,
//		0x00, 0x07, 0xff, 0xff, 0xff, 0xff, 0xff, 0xff, 0xff, 0xff, 0xe4, 0x3f, 0xff, 0xff, 0xff, 0xff,
//		0xff, 0xff, 0xff, 0xf0, 0xff, 0xff, 0xff, 0xff, 0xff, 0xff, 0xff, 0xff, 0xff, 0xff, 0xff, 0xc0,
//		0x00, 0xe0, 0x0f, 0xfc, 0x00, 0x00, 0x00, 0x0f, 0xff, 0xff, 0xff, 0xff, 0xff, 0xff, 0xff, 0xff,
//		0xe0, 0x3f, 0xff, 0xff, 0xff, 0xff, 0xff, 0xff, 0xff, 0xf0, 0xff, 0xff, 0xff, 0xff, 0xff, 0xff,
//		0xff, 0xff, 0xff, 0xff, 0xff, 0xe0, 0x00, 0x60, 0x0f, 0xfe, 0x00, 0x00, 0x00, 0x3f, 0xff, 0xff,
//		0xff, 0xff, 0xff, 0xff, 0xff, 0xff, 0xe0, 0x1f, 0xff, 0xff, 0xff, 0xff, 0xff, 0xff, 0xff, 0xf0,
//		0xff, 0xff, 0xff, 0xff, 0xff, 0xff, 0xff, 0xff, 0xff, 0xff, 0xff, 0xe0, 0x00, 0x30, 0x07, 0xfe,
//		0x80, 0x00, 0x00, 0x1f, 0xff, 0xff, 0xff, 0xff, 0xff, 0xff, 0xff, 0xff, 0xe0, 0x1f, 0xff, 0xff,
//		0xff, 0xff, 0xff, 0xff, 0xff, 0xf0, 0xff, 0xff, 0xff, 0xff, 0xff, 0xff, 0xff, 0xff, 0xff, 0xff,
//		0xff, 0xe0, 0x00, 0x38, 0x03, 0xff, 0x80, 0x00, 0x00, 0x03, 0xff, 0xff, 0xff, 0xff, 0xff, 0xff,
//		0xff, 0xff, 0xe0, 0x0f, 0xff, 0xff, 0xff, 0xff, 0xff, 0xff, 0xff, 0xf0, 0xff, 0xff, 0xff, 0xff,
//		0xff, 0xff, 0xff, 0xff, 0xff, 0xff, 0xff, 0xe0, 0x00, 0x38, 0x01, 0xff, 0xc0, 0x00, 0x80, 0x07,
//		0xff, 0xff, 0xff, 0xff, 0xff, 0xff, 0xff, 0xff, 0xe0, 0x47, 0xff, 0xff, 0xff, 0xff, 0xff, 0xff,
//		0xff, 0xf0, 0xff, 0xff, 0xff, 0xff, 0xff, 0xff, 0xff, 0xff, 0xff, 0xff, 0xff, 0xf0, 0x00, 0x08,
//		0x00, 0x7f, 0xf0, 0x07, 0xf8, 0x0f, 0xff, 0xff, 0xff, 0xff, 0xff, 0xff, 0xff, 0xff, 0xf0, 0x17,
//		0xff, 0xff, 0xff, 0xff, 0xff, 0xff, 0xff, 0xf0, 0xff, 0xff, 0xff, 0xff, 0xff, 0xff, 0xff, 0xff,
//		0xff, 0xff, 0xff, 0xf0, 0x00, 0x00, 0x00, 0x3f, 0xff, 0xff, 0xff, 0xff, 0xff, 0xff, 0xff, 0xff,
//		0xf8, 0xff, 0xff, 0xff, 0xe0, 0x0f, 0xff, 0xff, 0xff, 0xff, 0xff, 0xff, 0xff, 0xf0, 0xff, 0xff,
//		0xff, 0xff, 0xff, 0xff, 0xff, 0xff, 0xff, 0xff, 0xff, 0xf8, 0x00, 0x00, 0x00, 0x07, 0xff, 0x00,
//		0x00, 0xff, 0xff, 0xff, 0xff, 0xff, 0xe1, 0xdf, 0xff, 0xff, 0xe0, 0x0f, 0xff, 0xff, 0xff, 0xff,
//		0xff, 0xff, 0xff, 0xf0, 0xff, 0xff, 0xff, 0xff, 0xff, 0xff, 0xff, 0xff, 0xff, 0xff, 0xff, 0xf8,
//		0x00, 0x00, 0x00, 0x00, 0x00, 0x00, 0x00, 0x07, 0xff, 0xff, 0xff, 0xff, 0x83, 0xff, 0xff, 0xff,
//		0xe0, 0x07, 0xff, 0xff, 0xff, 0xff, 0xff, 0xff, 0xff, 0xf0, 0xff, 0xff, 0xff, 0xff, 0xff, 0xff,
//		0xff, 0xff, 0xff, 0xff, 0xff, 0xf8, 0x00, 0x00, 0x00, 0x00, 0x00, 0x00, 0x00, 0x07, 0xff, 0xff,
//		0xff, 0xfe, 0x07, 0xff, 0xff, 0xff, 0xfc, 0x17, 0xff, 0xff, 0xff, 0xff, 0xff, 0xff, 0xff, 0xf0,
//		0xff, 0xff, 0xff, 0xff, 0xff, 0xff, 0xff, 0xff, 0xff, 0xff, 0xff, 0xfc, 0x00, 0x00, 0x00, 0x00,
//		0x01, 0x00, 0x00, 0x1f, 0xe3, 0xff, 0xff, 0xfc, 0x0f, 0xff, 0xff, 0xff, 0xf2, 0x37, 0xff, 0xff,
//		0xff, 0xff, 0xff, 0xff, 0xff, 0xf0, 0xff, 0xff, 0xff, 0xff, 0xff, 0xff, 0xff, 0xff, 0xff, 0xff,
//		0xff, 0xfc, 0x00, 0x00, 0x00, 0x00, 0x02, 0x00, 0x00, 0x30, 0x00, 0x7f, 0xff, 0xf8, 0x3f, 0xff,
//		0xff, 0xff, 0xf0, 0x1f, 0xff, 0xff, 0xff, 0xff, 0xff, 0xff, 0xff, 0xf0, 0xff, 0xff, 0xff, 0xff,
//		0xff, 0xff, 0xff, 0xff, 0xff, 0xff, 0xff, 0xfc, 0x00, 0x00, 0x00, 0x00, 0x00, 0x80, 0x00, 0x30,
//		0x00, 0x0f, 0xff, 0xf8, 0x7f, 0xff, 0xff, 0xff, 0xe4, 0x0f, 0xff, 0xff, 0xff, 0xff, 0xff, 0xff,
//		0xff, 0xf0, 0xff, 0xff, 0xff, 0xff, 0xff, 0xff, 0xff, 0xff, 0xff, 0xff, 0xff, 0xfc, 0x00, 0x00,
//		0x00, 0x00, 0x01, 0xc0, 0x00, 0x70, 0x0f, 0xe0, 0xff, 0xf0, 0xff, 0xff, 0xff, 0xff, 0xc0, 0x03,
//		0xff, 0xff, 0xff, 0xff, 0xff, 0xff, 0xff, 0xf0, 0xff, 0xff, 0xff, 0xff, 0xff, 0xff, 0xff, 0xff,
//		0xff, 0xff, 0xff, 0xfc, 0x00, 0x00, 0x00, 0x00, 0x00, 0xc0, 0x00, 0xf0, 0xff, 0xff, 0x00, 0xe3,
//		0xff, 0xff, 0xff, 0xff, 0x80, 0x03, 0xff, 0xff, 0xff, 0xff, 0xff, 0xff, 0xff, 0xf0, 0xff, 0xff,
//		0xff, 0xff, 0xff, 0xff, 0xff, 0xff, 0xff, 0xff, 0xff, 0xfc, 0x00, 0x00, 0x00, 0x03, 0x00, 0xe0,
//		0x07, 0xf7, 0xff, 0xff, 0xff, 0x7f, 0xff, 0xef, 0xff, 0xff, 0x00, 0x01, 0xff, 0xff, 0xff, 0xff,
//		0xff, 0xff, 0xff, 0xf0, 0xff, 0xff, 0xff, 0xff, 0xff, 0xff, 0xff, 0xff, 0xff, 0xff, 0xff, 0xfe,
//		0x00, 0x00, 0x00, 0x03, 0x80, 0x1f, 0xff, 0xe7, 0xff, 0xff, 0xff, 0xfb, 0xff, 0xef, 0xff, 0xff,
//		0x00, 0x00, 0xff, 0xff, 0xff, 0xff, 0xff, 0xff, 0xff, 0xf0, 0xff, 0xff, 0xff, 0xff, 0xff, 0xff,
//		0xff, 0xff, 0xff, 0xff, 0xff, 0xfe, 0x00, 0x00, 0x00, 0x03, 0xc0, 0x01, 0xfc, 0x07, 0xff, 0xff,
//		0xff, 0xff, 0xff, 0xf1, 0xff, 0xff, 0x00, 0x00, 0x7f, 0xff, 0xff, 0xff, 0xff, 0xff, 0xff, 0xf0,
//		0xff, 0xff, 0xff, 0xff, 0xff, 0xff, 0xff, 0xff, 0xff, 0xff, 0xff, 0xfc, 0x00, 0x00, 0x00, 0x03,
//		0xc0, 0x00, 0x00, 0x07, 0xff, 0xff, 0xff, 0xfd, 0xff, 0xf0, 0x1f, 0x4f, 0x00, 0x00, 0xbf, 0xff,
//		0xff, 0xff, 0xff, 0xff, 0xff, 0xf0, 0xff, 0xff, 0xff, 0xff, 0xff, 0xff, 0xff, 0xff, 0xff, 0xff,
//		0xff, 0xff, 0x00, 0x00, 0x00, 0x03, 0xe0, 0x00, 0x00, 0x07, 0xff, 0xff, 0xff, 0xff, 0xff, 0x00,
//		0x09, 0x0f, 0x00, 0x01, 0xbf, 0xff, 0xff, 0xff, 0xff, 0xff, 0xff, 0xf0, 0xff, 0xff, 0xff, 0xff,
//		0xff, 0xff, 0xff, 0xff, 0xff, 0xff, 0xff, 0xfe, 0x00, 0x00, 0x00, 0x03, 0xf0, 0x00, 0x00, 0x07,
//		0xff, 0xff, 0xff, 0xff, 0xfe, 0x00, 0x00, 0x0f, 0x00, 0x00, 0xff, 0xff, 0xff, 0xff, 0xff, 0xff,
//		0xff, 0xf0, 0xff, 0xff, 0xff, 0xff, 0xff, 0xff, 0xff, 0xff, 0xff, 0xff, 0xff, 0xfe, 0x00, 0x00,
//		0x00, 0x07, 0xf0, 0x00, 0x00, 0x07, 0xff, 0xff, 0xff, 0xff, 0xff, 0x00, 0x06, 0x0f, 0x00, 0x00,
//		0xff, 0xff, 0xff, 0xff, 0xff, 0xff, 0xff, 0xf0, 0xff, 0xff, 0xff, 0xff, 0xff, 0xff, 0xff, 0xff,
//		0xff, 0xff, 0xff, 0xff, 0x00, 0x00, 0x00, 0x0f, 0xfc, 0x00, 0x00, 0x0f, 0xff, 0xff, 0xff, 0xff,
//		0xee, 0x00, 0x00, 0x0b, 0x00, 0x83, 0xff, 0xff, 0xff, 0xff, 0xff, 0xff, 0xff, 0xf0, 0xff, 0xff,
//		0xff, 0xff, 0xff, 0xff, 0xff, 0xff, 0xff, 0xff, 0xff, 0xfc, 0x00, 0x00, 0x00, 0x0f, 0xfe, 0x00,
//		0x00, 0x3f, 0xff, 0xff, 0xff, 0xff, 0xe0, 0x00, 0x00, 0x02, 0x08, 0x07, 0xff, 0xff, 0xff, 0xff,
//		0xff, 0xff, 0xff, 0xf0, 0xff, 0xff, 0xff, 0xff, 0xff, 0xff, 0xff, 0xff, 0xff, 0xff, 0xff, 0xf8,
//		0x00, 0x00, 0x00, 0x07, 0xff, 0x00, 0x00, 0x7f, 0xff, 0xff, 0xff, 0xff, 0xf8, 0x00, 0x00, 0x00,
//		0x09, 0x07, 0xff, 0xff, 0xff, 0xff, 0xff, 0xff, 0xff, 0xf0, 0xff, 0xff, 0xff, 0xff, 0xff, 0xff,
//		0xff, 0xff, 0xff, 0xff, 0xff, 0xe0, 0x00, 0x00, 0x00, 0x02, 0xff, 0xf0, 0x01, 0xff, 0xff, 0xff,
//		0xff, 0xff, 0xf8, 0x00, 0x00, 0x00, 0x08, 0x03, 0xff, 0xff, 0xff, 0xff, 0xff, 0xff, 0xff, 0xf0,
//		0xff, 0xff, 0xff, 0xff, 0xff, 0xff, 0xff, 0xff, 0xff, 0xff, 0xff, 0xc0, 0x00, 0x00, 0x00, 0x00,
//		0xff, 0xff, 0xff, 0xff, 0xff, 0xff, 0xff, 0xfd, 0xf8, 0x00, 0x00, 0x00, 0x02, 0x6f, 0xff, 0xff,
//		0xff, 0xff, 0xff, 0xff, 0xff, 0xf0, 0xff, 0xff, 0xff, 0xff, 0xff, 0xff, 0xff, 0xff, 0xff, 0xff,
//		0xff, 0x00, 0x00, 0x00, 0x00, 0x00, 0x3f, 0xff, 0xff, 0xff, 0xff, 0xff, 0xff, 0xfe, 0xfc, 0x00,
//		0x00, 0x00, 0x00, 0x3f, 0xff, 0xff, 0xff, 0xff, 0xff, 0xff, 0xff, 0xf0, 0xff, 0xff, 0xff, 0xff,
//		0xff, 0xff, 0xff, 0xff, 0xff, 0xff, 0xff, 0x18, 0x00, 0x00, 0x00, 0x00, 0x06, 0xff, 0xff, 0xff,
//		0xff, 0xff, 0xff, 0xff, 0x7c, 0x00, 0x00, 0x00, 0x04, 0x1f, 0xff, 0xff, 0xff, 0xff, 0xff, 0xff,
//		0xff, 0xf0, 0xff, 0xff, 0xff, 0xff, 0xff, 0xff, 0xff, 0xff, 0xff, 0xff, 0xfe, 0xff, 0xc0, 0x00,
//		0x00, 0x00, 0x00, 0x3e, 0xff, 0xff, 0xff, 0xff, 0xff, 0xff, 0xbc, 0x00, 0x00, 0x80, 0x04, 0x5f,
//		0xff, 0xff, 0xff, 0xff, 0xff, 0xff, 0xff, 0xf0, 0xff, 0xff, 0xff, 0xff, 0xff, 0xff, 0xff, 0xff,
//		0xff, 0xff, 0xff, 0xf8, 0x00, 0x00, 0x00, 0x00, 0x00, 0x0f, 0xff, 0xff, 0xff, 0xff, 0xff, 0xff,
//		0xfe, 0x00, 0x00, 0x00, 0x00, 0x7f, 0xff, 0xff, 0xff, 0xff, 0xff, 0xff, 0xff, 0xf0, 0xff, 0xff,
//		0xff, 0xff, 0xff, 0xff, 0xff, 0xff, 0xff, 0xff, 0xff, 0xfe, 0x00, 0x00, 0x00, 0x00, 0x00, 0x87,
//		0xff, 0xff, 0xff, 0xff, 0xff, 0xff, 0xfe, 0x00, 0x00, 0x20, 0x00, 0x3f, 0xff, 0xff, 0xff, 0xff,
//		0xff, 0xff, 0xff, 0xf0, 0xff, 0xff, 0xff, 0xff, 0xff, 0xff, 0xff, 0xff, 0xff, 0xff, 0xff, 0xfc,
//		0x00, 0x00, 0x00, 0x00, 0x00, 0x0f, 0xff, 0xff, 0xff, 0xff, 0xff, 0xff, 0xff, 0x00, 0x00, 0x00,
//		0x00, 0x3f, 0xff, 0xff, 0xff, 0xff, 0xff, 0xff, 0xff, 0xf0, 0xff, 0xff, 0xff, 0xff, 0xff, 0xff,
//		0xff, 0xff, 0xff, 0xff, 0xff, 0xfc, 0x00, 0x00, 0x00, 0x00, 0x00, 0xc7, 0xff, 0xff, 0xff, 0xff,
//		0xff, 0xff, 0xff, 0x80, 0x00, 0x10, 0x00, 0xff, 0xff, 0xff, 0xff, 0xff, 0xff, 0xff, 0xff, 0xf0,
//		0xff, 0xff, 0xff, 0xff, 0xff, 0xff, 0xff, 0xff, 0xff, 0xff, 0xff, 0xfc, 0x00, 0x00, 0x00, 0x00,
//		0x00, 0xcf, 0xff, 0xff, 0xff, 0xff, 0xff, 0xff, 0xff, 0xe0, 0x00, 0x08, 0x00, 0x7f, 0xff, 0xff,
//		0xff, 0xff, 0xff, 0xff, 0xff, 0xf0, 0xff, 0xff, 0xff, 0xff, 0xff, 0xff, 0xff, 0xff, 0xff, 0xff,
//		0xff, 0xfc, 0x00, 0x00, 0x00, 0x00, 0x00, 0xff, 0xff, 0xff, 0xff, 0xff, 0xff, 0xff, 0xff, 0xf8,
//		0x00, 0x04, 0x00, 0x7f, 0xff, 0xff, 0xff, 0xff, 0xff, 0xff, 0xff, 0xf0, 0xff, 0xff, 0xff, 0xff,
//		0xff, 0xff, 0xff, 0xff, 0xff, 0xff, 0xff, 0xf8, 0x00, 0x00, 0x00, 0x00, 0x00, 0xff, 0xff, 0xff,
//		0xff, 0xff, 0xff, 0xff, 0xfd, 0xfc, 0x00, 0x06, 0x00, 0xdf, 0xff, 0xff, 0xff, 0xff, 0xff, 0xff,
//		0xff, 0xf0, 0xff, 0xff, 0xff, 0xff, 0xff, 0xff, 0xff, 0xff, 0xff, 0xff, 0xff, 0xf8, 0x00, 0x00,
//		0x00, 0x00, 0x00, 0x7f, 0xff, 0xff, 0xff, 0xff, 0xff, 0xff, 0xff, 0xff, 0x20, 0x00, 0x09, 0xff,
//		0xff, 0xff, 0xff, 0xff, 0xff, 0xff, 0xff, 0xf0, 0xff, 0xff, 0xff, 0xff, 0xff, 0xff, 0xff, 0xff,
//		0xff, 0xff, 0xff, 0xf8, 0x00, 0x00, 0x00, 0x00, 0x00, 0x7f, 0xff, 0xff, 0xff, 0xff, 0xff, 0xff,
//		0xff, 0xff, 0x80, 0x00, 0x0f, 0xff, 0xff, 0xff, 0xff, 0xff, 0xff, 0xff, 0xff, 0xf0, 0xff, 0xff,
//		0xff, 0xff, 0xff, 0xff, 0xff, 0xff, 0xff, 0xff, 0xff, 0xf8, 0x00, 0x00, 0x03, 0x80, 0x0f, 0xff,
//		0xff, 0xff, 0xff, 0xff, 0xff, 0xff, 0xff, 0xff, 0x86, 0x00, 0x0f, 0x7f, 0xff, 0xff, 0xff, 0xff,
//		0xff, 0xff, 0xff, 0xf0, 0xff, 0xff, 0xff, 0xff, 0xff, 0xff, 0xff, 0xff, 0xff, 0xff, 0xff, 0xfe,
//		0x00, 0x00, 0x0f, 0x80, 0x1f, 0xff, 0xff, 0xff, 0xff, 0xff, 0xff, 0xff, 0xff, 0xff, 0xc3, 0x80,
//		0x07, 0xff, 0xff, 0xff, 0xff, 0xff, 0xff, 0xff, 0xff, 0xf0, 0xff, 0xff, 0xff, 0xff, 0xff, 0xff,
//		0xff, 0xff, 0xff, 0xff, 0xff, 0xfe, 0x00, 0x00, 0x1f, 0x80, 0x1f, 0xff, 0xff, 0xff, 0xff, 0xff,
//		0xff, 0xff, 0xff, 0xff, 0xc3, 0xe4, 0x0f, 0xff, 0xff, 0xff, 0xff, 0xff, 0xff, 0xff, 0xff, 0xf0,
//		0x0f, 0xff, 0xff, 0xff, 0xff, 0xff, 0xff, 0xff, 0xff, 0xff, 0xe3, 0xf0, 0x01, 0xff, 0xff, 0xff,
//		0xff, 0xff, 0xff, 0xff, 0xff, 0xf0, 0xff, 0xff, 0xff, 0xff, 0xff, 0xff, 0xff, 0xff, 0xff, 0xff,
//		0xff, 0xff, 0xe0, 0x00, 0xff, 0x00, 0x1f, 0xff, 0xff, 0xff, 0xff, 0xff, 0xff, 0xff, 0xff, 0xff,
//		0xf1, 0xfc, 0x0f, 0xff, 0xff, 0xff, 0xff, 0xff, 0xff, 0xff, 0xff, 0xf0, 0xff, 0xff, 0xff, 0xff,
//		0xff, 0xff, 0xff, 0xff, 0xff, 0xff, 0xff, 0xff, 0xf8, 0x07, 0xff, 0x10, 0x3f, 0xff, 0xff, 0xff,
//		0xff, 0xff, 0xff, 0xff, 0xff, 0xff, 0xf1, 0xfc, 0x7f, 0xff, 0xff, 0xff, 0xff, 0xff, 0xff, 0xff,
//		0xff, 0xf0, 0xff, 0xff, 0xff, 0xff, 0xff, 0xff, 0xff, 0xff, 0xff, 0xff, 0xff, 0xff, 0xff, 0x8f,
//		0xff, 0x3e, 0x7f, 0xff, 0xff, 0xff, 0xff, 0xff, 0xff, 0xff, 0xff, 0xff, 0xf8, 0xfe, 0xff, 0xff,
//		0xff, 0xff, 0xff, 0xff, 0xff, 0xff, 0xff, 0xf0, 0xff, 0xff, 0xff, 0xff, 0xff, 0xff, 0xff, 0xff,
//		0xff, 0xff, 0xff, 0xff, 0xff, 0xff, 0xfe, 0x3e, 0x7f, 0xff, 0xff, 0xff, 0xff, 0xff, 0xff, 0xff,
//		0xff, 0xff, 0xfc, 0xff, 0x7f, 0xff, 0xff, 0xff, 0xff, 0xff, 0xff, 0xff, 0xff, 0xf0, 0xff, 0xff,
//		0xff, 0xff, 0xff, 0xff, 0xff, 0xff, 0xff, 0xff, 0xff, 0xff, 0xff, 0xff, 0xfe, 0x7e, 0xff, 0xff,
//		0xff, 0xff, 0xff, 0xff, 0xff, 0xff, 0xff, 0xff, 0xfc, 0xff, 0xff, 0xff, 0xff, 0xff, 0xff, 0xff,
//		0xff, 0xff, 0xff, 0xf0, 0xff, 0xff, 0xff, 0xff, 0xff, 0xff, 0xff, 0xff, 0xff, 0xff, 0xff, 0xff,
//		0xff, 0xff, 0xff, 0xfe, 0xff, 0xff, 0xff, 0xff, 0xff, 0xff, 0xff, 0xff, 0xff, 0xff, 0xfe, 0xff,
//		0xff, 0xff, 0xff, 0xff, 0xff, 0xff, 0xff, 0xff, 0xff, 0xf0, 0xff, 0xff, 0xff, 0xff, 0xff, 0xff,
//		0xff, 0xff, 0xff, 0xff, 0xff, 0xff, 0xff, 0xff, 0xff, 0xff, 0xff, 0xff, 0xff, 0xff, 0xff, 0xff,
//		0xff, 0xff, 0xff, 0xff, 0xfe, 0x7f, 0xff, 0xff, 0xff, 0xff, 0xff, 0xff, 0xff, 0xff, 0xff, 0xf0,
//		0xff, 0xff, 0xff, 0xff, 0xff, 0xff, 0xff, 0xff, 0xff, 0xff, 0xff, 0xff, 0xff, 0xff, 0xff, 0xff,
//		0xff, 0xff, 0xff, 0xff, 0xff, 0xff, 0xff, 0xff, 0xff, 0xff, 0xfe, 0xff, 0xff, 0xff, 0xff, 0xff,
//		0xff, 0xff, 0xff, 0xff, 0xff, 0xf0, 0xff, 0xff, 0xff, 0xff, 0xff, 0xff, 0xff, 0xff, 0xff, 0xff,
//		0xff, 0xff, 0xff, 0xff, 0xff, 0xff, 0xff, 0xff, 0xff, 0xff, 0xff, 0xff, 0xff, 0xff, 0xff, 0xff,
//		0xff, 0xff, 0xff, 0xff, 0xff, 0xff, 0xff, 0xff, 0xff, 0xff, 0xff, 0xf0, 0xff, 0xff, 0xff, 0xff,
//		0xff, 0xff, 0xff, 0xff, 0xff, 0xff, 0xff, 0xff, 0xff, 0xff, 0xff, 0xff, 0xff, 0xff, 0xff, 0xff,
//		0xff, 0xff, 0xff, 0xff, 0xff, 0xff, 0xff, 0xff, 0xff, 0xff, 0xff, 0xff, 0xff, 0xff, 0xff, 0xff,
//		0xff, 0xf0, 0xff, 0xff, 0xff, 0xff, 0xff, 0xff, 0xff, 0xff, 0xff, 0xff, 0xff, 0xff, 0xff, 0xff,
//		0xff, 0xff, 0xff, 0xff, 0xff, 0xff, 0xff, 0xff, 0xff, 0xff, 0xff, 0xff, 0xff, 0xff, 0xff, 0xff,
//		0xff, 0xff, 0xff, 0xff, 0xff, 0xff, 0xff, 0xf0, 0xff, 0xff, 0xff, 0xff, 0xff, 0xff, 0xff, 0xff,
//		0xff, 0xff, 0xff, 0xff, 0xff, 0xff, 0xff, 0xff, 0xff, 0xff, 0xff, 0xff, 0xff, 0xff, 0xff, 0xff,
//		0xff, 0xff, 0xff, 0xff, 0xff, 0xff, 0xff, 0xff, 0xff, 0xff, 0xff, 0xff, 0xff, 0xf0, 0xff, 0xff,
//		0xff, 0xff, 0xff, 0xff, 0xff, 0xff, 0xff, 0xff, 0xff, 0xff, 0xff, 0xff, 0xff, 0xff, 0xff, 0xff,
//		0xff, 0xff, 0xff, 0xff, 0xff, 0xff, 0xff, 0xff, 0xff, 0xff, 0xff, 0xff, 0xff, 0xff, 0xff, 0xff,
//		0xff, 0xff, 0xff, 0xf0, 0xff, 0xff, 0xff, 0xff, 0xff, 0xff, 0xff, 0xff, 0xff, 0xff, 0xff, 0xff,
//		0xff, 0xff, 0xff, 0xff, 0xff, 0xff, 0xff, 0xff, 0xff, 0xff, 0xff, 0xff, 0xff, 0xff, 0xff, 0xff,
//		0xff, 0xff, 0xff, 0xff, 0xff, 0xff, 0xff, 0xff, 0xff, 0xf0, 0xff, 0xff, 0xff, 0xff, 0xff, 0xff,
//		0xff, 0xff, 0xff, 0xff, 0xff, 0xff, 0xff, 0xff, 0xff, 0xff, 0xff, 0xff, 0xff, 0xff, 0xff, 0xff,
//		0xff, 0xff, 0xff, 0xff, 0xff, 0xff, 0xff, 0xff, 0xff, 0xff, 0xff, 0xff, 0xff, 0xff, 0xff, 0xf0,
//		0xff, 0xff, 0xff, 0xff, 0xff, 0xff, 0xff, 0xff, 0xff, 0xf7, 0xff, 0xff, 0xff, 0xff, 0xff, 0xff,
//		0xff, 0xff, 0xff, 0xff, 0xff, 0xff, 0xff, 0xff, 0xff, 0xff, 0xff, 0xff, 0xff, 0xff, 0xff, 0xff,
//		0xff, 0xff, 0xff, 0xff, 0xff, 0xf0, 0xff, 0xff, 0xff, 0xff, 0xff, 0xff, 0xff, 0xff, 0xff, 0xff,
//		0xff, 0xff, 0xff, 0xff, 0xff, 0xff, 0xff, 0xff, 0xff, 0xff, 0xff, 0xff, 0xff, 0xff, 0xff, 0xff,
//		0xff, 0xff, 0xff, 0xff, 0xff, 0xff, 0xff, 0xff, 0xff, 0xff, 0xff, 0xf0, 0xff, 0xff, 0xff, 0xff,
//		0xff, 0xff, 0xff, 0xff, 0xcf, 0x8f, 0xff, 0xff, 0xff, 0xff, 0xff, 0xff, 0xff, 0xff, 0xff, 0xff,
//		0xff, 0xff, 0xff, 0xff, 0xff, 0xff, 0xff, 0xff, 0xff, 0xff, 0xff, 0xff, 0xff, 0xff, 0xff, 0xff,
//		0xff, 0xf0, 0xff, 0xff, 0xff, 0xff, 0xff, 0xff, 0xff, 0xff, 0xcf, 0x81, 0xff, 0xff, 0xff, 0xff,
//		0xff, 0xff, 0xff, 0xff, 0xff, 0xff, 0xff, 0xff, 0xff, 0xff, 0xff, 0xff, 0xff, 0xff, 0xff, 0xff,
//		0xff, 0xff, 0xff, 0xff, 0xff, 0xff, 0xff, 0xf0, 0xff, 0xff, 0xff, 0xff, 0xff, 0xff, 0xff, 0xff,
//		0xc3, 0x00, 0xff, 0xff, 0xff, 0xff, 0xff, 0xff, 0xff, 0xff, 0xff, 0xff, 0xff, 0xff, 0xff, 0xff,
//		0xff, 0xff, 0xff, 0xff, 0xff, 0xff, 0xff, 0xff, 0xff, 0xff, 0xff, 0xff, 0xff, 0xf0, 0xff, 0xff,
//		0xff, 0xff, 0xff, 0xff, 0xff, 0xff, 0x81, 0x01, 0x7f, 0xff, 0xff, 0xff, 0xff, 0xff, 0xff, 0xff,
//		0xff, 0xff, 0xff, 0xff, 0xff, 0xff, 0xff, 0xff, 0xff, 0xff, 0xff, 0xff, 0xff, 0xff, 0xff, 0xff,
//		0xff, 0xff, 0xff, 0xf0, 0xff, 0xff, 0xff, 0xff, 0xff, 0xff, 0xff, 0xff, 0x81, 0x00, 0x3f, 0xff,
//		0xff, 0xff, 0xff, 0xff, 0xff, 0xff, 0xff, 0xff, 0xff, 0xff, 0xff, 0xff, 0xff, 0xff, 0xff, 0xff,
//		0xff, 0xff, 0xff, 0xff, 0xff, 0xff, 0xff, 0xff, 0xff, 0xf0, 0xff, 0xff, 0xff, 0xff, 0xff, 0xff,
//		0xff, 0xff, 0x00, 0x00, 0x3e, 0xff, 0xff, 0xff, 0xff, 0xff, 0xff, 0xff, 0xff, 0xff, 0xff, 0xff,
//		0xff, 0xff, 0xff, 0xff, 0xff, 0xff, 0xff, 0xff, 0xff, 0xff, 0xff, 0xff, 0xff, 0xff, 0xff, 0xf0,
//		0xff, 0xff, 0xff, 0xff, 0xff, 0xff, 0xff, 0xff, 0x00, 0x00, 0x19, 0x3f, 0xff, 0xff, 0xff, 0xff,
//		0xff, 0xff, 0xff, 0xff, 0xff, 0xff, 0xff, 0xff, 0xff, 0xff, 0xff, 0xff, 0xff, 0xff, 0xff, 0xff,
//		0xff, 0xff, 0xff, 0xff, 0xff, 0xf0, 0xff, 0xff, 0xff, 0xff, 0xff, 0xff, 0xff, 0xff, 0x00, 0x00,
//		0x1c, 0x2f, 0xff, 0xff, 0xff, 0xff, 0xff, 0xff, 0xff, 0xff, 0xff, 0xff, 0xff, 0xff, 0xff, 0xff,
//		0xff, 0xff, 0xff, 0xff, 0xff, 0xff, 0xff, 0xff, 0xff, 0xff, 0xff, 0xf0, 0xff, 0xff, 0xff, 0xff,
//		0xff, 0xff, 0xff, 0xff, 0x00, 0x00, 0x04, 0x0f, 0xff, 0xff, 0xff, 0xff, 0xff, 0xff, 0xff, 0xff,
//		0xff, 0xff, 0xff, 0xff, 0xff, 0xff, 0xff, 0xff, 0xff, 0xff, 0xff, 0xff, 0xff, 0xff, 0xff, 0xff,
//		0xff, 0xf0, 0xff, 0xff, 0xff, 0xff, 0xff, 0xff, 0xff, 0xff, 0x00, 0x00, 0x00, 0x0f, 0xff, 0xff,
//		0xff, 0xff, 0xff, 0xff, 0xff, 0xff, 0xff, 0xff, 0xff, 0xff, 0xff, 0xff, 0xff, 0xff, 0xff, 0xff,
//		0xff, 0xff, 0xff, 0xff, 0xff, 0xff, 0xff, 0xf0, 0xff, 0xff, 0xff, 0xff, 0xff, 0xff, 0xff, 0xff,
//		0x00, 0x00, 0x00, 0x0f, 0xff, 0xff, 0xff, 0xff, 0xff, 0xff, 0xff, 0xff, 0xff, 0xff, 0xff, 0xff,
//		0xff, 0xff, 0xff, 0xff, 0xff, 0xff, 0xff, 0xff, 0xff, 0xff, 0xff, 0xff, 0xff, 0xf0, 0xff, 0xff,
//		0xff, 0xff, 0xff, 0xff, 0xff, 0xfe, 0x00, 0x00, 0x00, 0x07, 0x9f, 0xff, 0xff, 0xff, 0xff, 0xff,
//		0xff, 0xff, 0xff, 0xff, 0xff, 0xff, 0xff, 0xff, 0xff, 0xff, 0xff, 0xff, 0xff, 0xff, 0xff, 0xff,
//		0xff, 0xff, 0xff, 0xf0, 0xff, 0xff, 0xff, 0xff, 0xff, 0xff, 0xff, 0xfe, 0x00, 0x00, 0x00, 0x03,
//		0x8f, 0xff, 0xff, 0xff, 0xff, 0xff, 0xff, 0xff, 0xff, 0xff, 0xff, 0xff, 0xff, 0xff, 0xff, 0xff,
//		0xff, 0xff, 0xff, 0xff, 0xff, 0xff, 0xff, 0xff, 0xff, 0xf0, 0xff, 0xff, 0xff, 0xff, 0xff, 0xff,
//		0xff, 0xfc, 0x00, 0x00, 0x00, 0x03, 0x0f, 0xff, 0xff, 0xff, 0xff, 0xff, 0xff, 0xff, 0xff, 0xff,
//		0xff, 0xff, 0xff, 0xff, 0xff, 0xff, 0xff, 0xff, 0xff, 0xff, 0xff, 0xff, 0xff, 0xff, 0xff, 0xf0,
//		0xff, 0xff, 0xff, 0xff, 0xff, 0xff, 0xff, 0xfc, 0x00, 0x00, 0x00, 0x01, 0x07, 0xff, 0xff, 0xff,
//		0xff, 0xff, 0xff, 0xff, 0xff, 0xff, 0xff, 0xff, 0xff, 0xff, 0xff, 0xff, 0xff, 0xff, 0xff, 0xff,
//		0xff, 0xff, 0xff, 0xff, 0xff, 0xf0, 0xff, 0xff, 0xff, 0xff, 0xff, 0xff, 0xff, 0xfc, 0x00, 0x00,
//		0x00, 0x01, 0x87, 0xff, 0xff, 0xff, 0xff, 0xff, 0xff, 0xff, 0xff, 0xff, 0xff, 0xff, 0xff, 0xff,
//		0xff, 0xff, 0xff, 0xff, 0xff, 0xff, 0xff, 0xff, 0xff, 0xff, 0xff, 0xf0, 0xff, 0xff, 0xff, 0xff,
//		0xff, 0xff, 0xff, 0xfc, 0x00, 0x00, 0x00, 0x01, 0x83, 0xff, 0xff, 0xff, 0xff, 0xff, 0xff, 0xff,
//		0xff, 0xff, 0xff, 0xff, 0xff, 0xff, 0xff, 0xff, 0xff, 0xff, 0xff, 0xff, 0xff, 0xff, 0xff, 0xff,
//		0xff, 0xf0, 0xff, 0xff, 0xff, 0xff, 0xff, 0xff, 0xff, 0xfc, 0x00, 0x00, 0x00, 0x00, 0x01, 0x1f,
//		0xff, 0xff, 0xff, 0xff, 0xff, 0xff, 0xff, 0xff, 0xff, 0xff, 0xff, 0xff, 0xff, 0xff, 0xff, 0xff,
//		0xff, 0xff, 0xff, 0xff, 0xff, 0xff, 0xff, 0xf0, 0xff, 0xff, 0xff, 0xff, 0xff, 0xff, 0xff, 0xf8,
//		0x00, 0x00, 0x00, 0x00, 0x00, 0x0f, 0xff, 0xff, 0xff, 0xff, 0xff, 0xff, 0xff, 0xff, 0xff, 0xff,
//		0xff, 0xff, 0xff, 0xff, 0xff, 0xff, 0xff, 0xff, 0xff, 0xff, 0xff, 0xff, 0xff, 0xf0, 0xff, 0xff,
//		0xff, 0xff, 0xff, 0xff, 0xff, 0xf8, 0x00, 0x00, 0x00, 0x00, 0x00, 0x07, 0xff, 0xff, 0xff, 0xff,
//		0xff, 0xff, 0xff, 0xff, 0xff, 0xff, 0xff, 0xff, 0xff, 0xff, 0xff, 0xff, 0xff, 0xff, 0xff, 0xff,
//		0xff, 0xff, 0xff, 0xf0, 0xff, 0xff, 0xff, 0xff, 0xff, 0xff, 0xff, 0xf8, 0x00, 0x00, 0x00, 0x00,
//		0x00, 0x00, 0x7f, 0xff, 0xff, 0xff, 0xff, 0xff, 0xff, 0xff, 0xff, 0xff, 0xff, 0xff, 0xff, 0xff,
//		0xff, 0xff, 0xff, 0xff, 0xff, 0xff, 0xff, 0xff, 0xff, 0xf0, 0xff, 0xff, 0xff, 0xff, 0xff, 0xff,
//		0xff, 0xf8, 0x00, 0x00, 0x00, 0x00, 0x00, 0x00, 0x33, 0xff, 0xff, 0xff, 0xff, 0xff, 0xff, 0xff,
//		0xff, 0xff, 0xff, 0xff, 0xff, 0xff, 0xff, 0xff, 0xff, 0xff, 0xff, 0xff, 0xff, 0xff, 0xff, 0xf0,
//		0xff, 0xff, 0xff, 0xff, 0xff, 0xff, 0xff, 0xf8, 0x00, 0x00, 0x00, 0x00, 0x00, 0x00, 0x09, 0xff,
//		0xff, 0xff, 0xff, 0xff, 0xff, 0xff, 0xff, 0xff, 0xff, 0xff, 0xff, 0xff, 0xff, 0xff, 0xff, 0xff,
//		0xff, 0xff, 0xff, 0xff, 0xff, 0xf0, 0xff, 0xff, 0xff, 0xff, 0xff, 0xff, 0xff, 0xf0, 0x00, 0x00,
//		0x00, 0x00, 0x00, 0x00, 0x00, 0xff, 0xff, 0xff, 0xff, 0xff, 0xff, 0xff, 0xff, 0xff, 0xff, 0xff,
//		0xff, 0xff, 0xff, 0xff, 0xff, 0xff, 0xff, 0xff, 0xff, 0xff, 0xff, 0xf0, 0xff, 0xff, 0xff, 0xff,
//		0xff, 0xff, 0xff, 0xf0, 0x00, 0x00, 0x00, 0x00, 0x00, 0x00, 0x00, 0x1f, 0xff, 0xff, 0xff, 0xff,
//		0xff, 0xff, 0xff, 0xff, 0xff, 0xff, 0xff, 0xff, 0xff, 0xff, 0xff, 0xff, 0xff, 0xff, 0xff, 0xff,
//		0xff, 0xf0, 0xff, 0xff, 0xff, 0xff, 0xff, 0xff, 0xff, 0xf0, 0x00, 0x00, 0x00, 0x00, 0x00, 0x00,
//		0x00, 0x1f, 0xff, 0xff, 0xff, 0xff, 0xff, 0xff, 0xff, 0xff, 0xff, 0xff, 0xff, 0xff, 0xff, 0xff,
//		0xff, 0xff, 0xff, 0xff, 0xff, 0xff, 0xff, 0xf0, 0xff, 0xff, 0xff, 0xff, 0xff, 0xff, 0xff, 0xf0,
//		0x00, 0x00, 0x00, 0x00, 0x00, 0x00, 0x00, 0x0f, 0xff, 0xff, 0xff, 0xff, 0xff, 0xff, 0xff, 0xff,
//		0xff, 0xff, 0xff, 0xff, 0xff, 0xff, 0xff, 0xff, 0xff, 0xff, 0xff, 0xff, 0xff, 0xf0, 0xff, 0xff,
//		0xff, 0xff, 0xff, 0xff, 0xff, 0xf0, 0x00, 0x00, 0x00, 0x00, 0x00, 0x00, 0x00, 0x03, 0xff, 0xff,
//		0xff, 0xff, 0xff, 0xff, 0xff, 0xff, 0xff, 0xff, 0xff, 0xff, 0xff, 0xff, 0xff, 0xff, 0xff, 0xff,
//		0xff, 0xff, 0xff, 0xf0, 0xff, 0xff, 0xff, 0xff, 0xff, 0xff, 0xff, 0xf0, 0x00, 0x00, 0x00, 0x00,
//		0x00, 0x00, 0x00, 0x02, 0xff, 0xff, 0xff, 0xff, 0xff, 0xff, 0xff, 0xff, 0xff, 0xff, 0xff, 0xff,
//		0xff, 0xff, 0xff, 0xff, 0xff, 0xff, 0xff, 0xff, 0xff, 0xf0, 0xff, 0xff, 0xff, 0xff, 0xff, 0xff,
//		0xff, 0xe0, 0x00, 0x00, 0x00, 0x00, 0x00, 0x00, 0x00, 0x00, 0x7f, 0xff, 0xff, 0xff, 0xff, 0xff,
//		0xff, 0xff, 0xff, 0xff, 0xff, 0xff, 0xff, 0xff, 0xff, 0xff, 0xff, 0xff, 0xff, 0xff, 0xff, 0xf0,
//		0xff, 0xff, 0xff, 0xff, 0xff, 0xff, 0xff, 0xe0, 0x00, 0x00, 0x00, 0x00, 0x00, 0x00, 0x00, 0x00,
//		0x3f, 0xff, 0xff, 0xff, 0xff, 0xff, 0xff, 0xff, 0xff, 0xff, 0xff, 0xff, 0xff, 0xff, 0xff, 0xff,
//		0xff, 0xff, 0xff, 0xff, 0xff, 0xf0, 0xff, 0xff, 0xff, 0xff, 0xff, 0xff, 0xff, 0xe0, 0x00, 0x00,
//		0x00, 0x00, 0x00, 0x00, 0x00, 0x00, 0x1f, 0xff, 0xff, 0xff, 0xff, 0xff, 0xff, 0xff, 0xff, 0xff,
//		0xff, 0xff, 0xff, 0xff, 0xff, 0xff, 0xff, 0xff, 0xff, 0xff, 0xff, 0xf0, 0xff, 0xff, 0xff, 0xff,
//		0xff, 0xff, 0xff, 0xe0, 0x00, 0x00, 0x00, 0x00, 0x00, 0x00, 0x00, 0x00, 0x07, 0xff, 0xff, 0xff,
//		0xff, 0xff, 0xff, 0xff, 0xff, 0xff, 0xff, 0xff, 0xff, 0xff, 0xff, 0xff, 0xff, 0xff, 0xff, 0xff,
//		0xff, 0xf0, 0xff, 0xff, 0xff, 0xff, 0xff, 0xff, 0xff, 0xe0, 0x00, 0x00, 0x00, 0x00, 0x00, 0x00,
//		0x00, 0x00, 0x07, 0xff, 0xff, 0xff, 0xff, 0xff, 0xff, 0xff, 0xff, 0xff, 0xff, 0xff, 0xff, 0xff,
//		0xff, 0xff, 0xff, 0xff, 0xff, 0xff, 0xff, 0xf0, 0xff, 0xff, 0xff, 0xff, 0xff, 0xff, 0xff, 0xf0,
//		0x00, 0x00, 0x00, 0x00, 0x00, 0x00, 0x00, 0x00, 0x07, 0xff, 0xff, 0xff, 0xff, 0xff, 0xff, 0xff,
//		0xff, 0xff, 0xff, 0xff, 0xff, 0xff, 0xff, 0xff, 0xff, 0xff, 0xff, 0xff, 0xff, 0xf0, 0xff, 0xff,
//		0xff, 0xff, 0xff, 0xff, 0xff, 0xf0, 0x00, 0x00, 0x00, 0x00, 0x00, 0x00, 0x00, 0x00, 0x07, 0xff,
//		0xff, 0xff, 0xff, 0xff, 0xff, 0xff, 0xff, 0xff, 0xff, 0xff, 0xff, 0xff, 0xff, 0xff, 0xff, 0xff,
//		0xff, 0xff, 0xff, 0xf0, 0xff, 0xff, 0xff, 0xff, 0xff, 0xff, 0xff, 0xf8, 0x00, 0x00, 0x00, 0x00,
//		0x00, 0x00, 0x00, 0x00, 0x7f, 0xff, 0xff, 0xff, 0xff, 0xff, 0xff, 0xff, 0xff, 0xff, 0xff, 0xff,
//		0xff, 0xff, 0xff, 0xff, 0xff, 0xff, 0xff, 0xff, 0xff, 0xf0, 0xff, 0xff, 0xff, 0xff, 0xff, 0xff,
//		0xff, 0xfc, 0x00, 0x00, 0x00, 0x00, 0x00, 0x00, 0x00, 0x67, 0xff, 0xff, 0xff, 0xff, 0xff, 0xff,
//		0xff, 0xff, 0xff, 0xff, 0xff, 0xff, 0xff, 0xff, 0xff, 0xff, 0xff, 0xff, 0xff, 0xff, 0xff, 0xf0
//};
const char  Image[1024]	={0x00, 0x00, 0x00, 0x00, 0x00, 0x00, 0x00, 0x00, 0x00, 0x00, 0x00, 0x00, 0x00, 0x00, 0x00, 0x00, 0x00, 0x00, 0x00, 0x00, 0x80, 0x80, 0x00, 0x80, 0xC0, 0x30, 0x58, 0x28, 0xB0, 0xD4, 0x54, 0x90, 0x68, 0xCC, 0x9E, 0xF2, 0xF2, 0xF2, 0x2C, 0x68, 0x20, 0xAC, 0x68, 0x4A, 0x50, 0x50, 0x18, 0x70, 0x71, 0x40, 0x09, 0xA8, 0xB0, 0x94, 0xD4, 0x64, 0x68, 0xAC, 0x80, 0xF1, 0x68, 0x6C, 0xAC, 0xB0, 0xD8, 0x8C, 0x8E, 0x32, 0x30, 0x32, 0x9C, 0xF8, 0xB4, 0x60, 0xD0, 0x60, 0x00, 0x00, 0xC0, 0x40, 0x80, 0x00, 0x00, 0x00, 0x00, 0x00, 0x00, 0x00, 0x00, 0x00, 0x00, 0x00, 0x00, 0x00, 0x00, 0x00, 0x00, 0x00, 0x00, 0x00, 0x00, 0x00, 0x00, 0x00, 0x00, 0x00, 0x00, 0x00, 0x00, 0x00, 0x00, 0x00, 0x00, 0x00, 0x00, 0x00, 0x00, 0x00, 0x00, 0x00, 0x00, 0x00, 0x00, 0x00, 0x00, 0x00, 0x00, 0x00,
0x00, 0x00, 0x00, 0x00, 0x00, 0x00, 0x00, 0x00, 0x00, 0x00, 0x00, 0x00, 0x00, 0x00, 0x00, 0x00, 0x00, 0x00, 0x08, 0x18, 0x25, 0x57, 0x0C, 0x4B, 0x19, 0x7A, 0x95, 0xDB, 0xA4, 0x33, 0x2F, 0x14, 0x88, 0x43, 0x41, 0x24, 0xA2, 0xD0, 0x33, 0x57, 0x0F, 0xF3, 0x72, 0x33, 0x1B, 0xFD, 0x6D, 0x4C, 0xA6, 0x59, 0x23, 0x2E, 0x3A, 0x03, 0x05, 0x05, 0x05, 0x01, 0x01, 0x04, 0x0C, 0x0B, 0x03, 0x04, 0x8A, 0x05, 0x05, 0x0F, 0x0A, 0x13, 0x15, 0x14, 0x06, 0x05, 0x13, 0x00, 0x04, 0x00, 0x00, 0x01, 0x00, 0x01, 0x04, 0x00, 0x00, 0x00, 0x00, 0x00, 0x00, 0x00, 0x00, 0x00, 0x00, 0x00, 0x00, 0x00, 0x00, 0x00, 0x00, 0x00, 0x00, 0x00, 0x00, 0x00, 0x00, 0x00, 0x00, 0x00, 0x00, 0x00, 0x00, 0x00, 0x00, 0x00, 0x00, 0x00, 0x00, 0x00, 0x00, 0x00, 0x00, 0x00, 0x00, 0x00, 0x00, 0x00, 0x00, 0x00,
0x00, 0x00, 0x00, 0x00, 0x00, 0x00, 0x00, 0x00, 0x00, 0x00, 0x00, 0x00, 0x00, 0x00, 0x00, 0x00, 0x00, 0x00, 0x00, 0x00, 0x00, 0x00, 0x00, 0x00, 0x01, 0x00, 0x00, 0x04, 0x01, 0x02, 0x08, 0x00, 0x00, 0x00, 0x00, 0x01, 0x00, 0x00, 0x01, 0x00, 0x00, 0x01, 0x00, 0x00, 0x01, 0x01, 0x00, 0x00, 0x00, 0x00, 0x80, 0x18, 0x00, 0x40, 0x40, 0x84, 0xEA, 0xA6, 0x74, 0x55, 0x14, 0x35, 0x05, 0x08, 0x22, 0x3D, 0x03, 0x1C, 0x8F, 0x02, 0x10, 0x98, 0x88, 0x80, 0x90, 0x58, 0x68, 0x68, 0x78, 0x50, 0x90, 0x60, 0xB0, 0x60, 0x40, 0xC0, 0x80, 0x80, 0x00, 0x00, 0x00, 0x00, 0x00, 0x00, 0x00, 0x00, 0x00, 0x00, 0x00, 0x00, 0x00, 0x00, 0x00, 0x00, 0x00, 0x00, 0x00, 0x00, 0x00, 0x00, 0x00, 0x00, 0x00, 0x00, 0x00, 0x00, 0x00, 0x00, 0x00, 0x00, 0x00, 0x00, 0x00, 0x00, 0x00, 0x00, 0x00, 0x00,
0x00, 0x00, 0x00, 0x00, 0x00, 0x00, 0x00, 0x00, 0x00, 0x00, 0x00, 0x00, 0x00, 0x00, 0x00, 0x00, 0x00, 0x00, 0x00, 0x00, 0x00, 0x00, 0x00, 0x00, 0x00, 0x00, 0x00, 0x00, 0x00, 0x00, 0x00, 0x00, 0x00, 0x00, 0x00, 0x01, 0x02, 0x00, 0x00, 0x00, 0x00, 0x00, 0x00, 0x00, 0x00, 0x00, 0x00, 0x00, 0x00, 0x00, 0x00, 0x01, 0x02, 0x08, 0x0A, 0x8B, 0x08, 0x85, 0x02, 0x02, 0xC0, 0x40, 0x02, 0xA1, 0x60, 0xA3, 0x20, 0x63, 0xDA, 0xD1, 0x69, 0x50, 0x50, 0xE8, 0xA8, 0xC8, 0xE8, 0xA8, 0xA8, 0x19, 0xE9, 0xB0, 0xA0, 0x69, 0x49, 0x55, 0x12, 0x2D, 0x45, 0x54, 0x94, 0xC8, 0x20, 0x80, 0x40, 0x30, 0x00, 0xC0, 0x00, 0x10, 0x10, 0x00, 0x30, 0x40, 0x40, 0x80, 0x00, 0x00, 0x00, 0x00, 0x00, 0x00, 0x00, 0x00, 0x00, 0x00, 0x10, 0x00, 0xB0, 0x80, 0xA0, 0xA0, 0x00, 0x00, 0xC0, 0x40, 0x00, 0xA0,
0x00, 0x00, 0x00, 0x00, 0x00, 0x00, 0x00, 0x00, 0x00, 0x00, 0x00, 0x00, 0x00, 0x00, 0x00, 0x00, 0x00, 0x00, 0x00, 0x00, 0x00, 0x00, 0x00, 0x00, 0x00, 0x00, 0x00, 0xC0, 0x00, 0x40, 0x40, 0x80, 0xA0, 0x60, 0x40, 0x80, 0xA0, 0x80, 0x00, 0xA0, 0x80, 0x20, 0xA0, 0x80, 0x80, 0x40, 0x20, 0xA0, 0xE0, 0x50, 0xA0, 0x28, 0x88, 0x40, 0x60, 0x00, 0x91, 0x19, 0x20, 0x11, 0x4A, 0x35, 0xAF, 0x52, 0xA2, 0xA2, 0xA5, 0x03, 0x84, 0x00, 0x40, 0x85, 0x05, 0x02, 0x04, 0x03, 0x05, 0x02, 0x22, 0x25, 0x26, 0x80, 0x44, 0x45, 0x03, 0xB2, 0x60, 0x03, 0x92, 0x23, 0x12, 0x10, 0x21, 0x00, 0x11, 0x00, 0x10, 0x10, 0x20, 0x30, 0x00, 0x08, 0x10, 0x0A, 0x00, 0x00, 0x04, 0x80, 0x80, 0x80, 0x60, 0x00, 0x08, 0x00, 0x04, 0x0C, 0x15, 0x13, 0x1A, 0x15, 0x0B, 0x34, 0xB5, 0xAD, 0x68, 0x54, 0x17, 0xDA,
0x00, 0x00, 0x00, 0x00, 0x80, 0xA0, 0x20, 0x40, 0xA0, 0x30, 0xA0, 0xC0, 0x30, 0xDC, 0xA8, 0x4C, 0x92, 0x92, 0x92, 0x92, 0x92, 0x92, 0x92, 0x92, 0xFE, 0xFF, 0xFE, 0xFF, 0xFE, 0xFF, 0xFF, 0xFE, 0xFF, 0xFF, 0xFF, 0xFF, 0xFE, 0xFE, 0xFF, 0xFF, 0xFE, 0xFF, 0xFF, 0xFE, 0xFF, 0xFF, 0xFE, 0xFE, 0x8C, 0xD7, 0xD2, 0x70, 0x69, 0x08, 0x00, 0x51, 0x01, 0x04, 0x04, 0x02, 0x01, 0x02, 0x05, 0x00, 0x00, 0x00, 0x00, 0x00, 0x01, 0x00, 0x00, 0x00, 0x00, 0x00, 0x00, 0x00, 0x00, 0x00, 0x00, 0x00, 0x00, 0x00, 0x00, 0x00, 0x00, 0x00, 0x00, 0x00, 0x00, 0x00, 0x00, 0x00, 0x00, 0x00, 0x00, 0x00, 0x00, 0x00, 0x20, 0x10, 0x10, 0x10, 0x10, 0x02, 0x04, 0x09, 0x04, 0x01, 0x0A, 0x02, 0x00, 0x00, 0x00, 0x00, 0x00, 0x00, 0x00, 0x00, 0x00, 0x00, 0x00, 0x00, 0x00, 0x00, 0x00, 0x01, 0x00, 0x02,
0xFE, 0xFF, 0xFF, 0xFE, 0xFF, 0xFE, 0xFE, 0xFF, 0xFE, 0xFF, 0xFF, 0xFE, 0xFF, 0xFE, 0xFF, 0xFF, 0xFF, 0xFF, 0xFF, 0xFF, 0xFF, 0xFF, 0xFF, 0xFF, 0xFF, 0xFF, 0xFF, 0xFF, 0xFF, 0xFF, 0xFF, 0xFF, 0xFF, 0xFF, 0xFF, 0xFF, 0xFF, 0xFF, 0xFF, 0xFF, 0xFF, 0xFF, 0xFF, 0xFF, 0xFF, 0xFF, 0xFF, 0xFF, 0xFE, 0xFF, 0xFE, 0xFE, 0xFF, 0xFF, 0xFF, 0xFF, 0x21, 0x18, 0x20, 0x08, 0x08, 0x08, 0x00, 0x08, 0x00, 0x00, 0x00, 0x00, 0x00, 0x00, 0x00, 0x00, 0x00, 0x00, 0x00, 0x00, 0x00, 0x00, 0x00, 0x00, 0x00, 0x00, 0x00, 0x00, 0x00, 0x00, 0x00, 0x00, 0x00, 0x00, 0x00, 0x00, 0x00, 0x00, 0x00, 0x00, 0x00, 0x00, 0x00, 0x00, 0x00, 0x00, 0x00, 0x00, 0x00, 0x00, 0x00, 0x00, 0x00, 0x00, 0x00, 0x00, 0x00, 0x00, 0x00, 0x00, 0x00, 0x00, 0x00, 0x00, 0x00, 0x00, 0x00, 0x00, 0x00, 0x00, 0x00, 0x00,
0x01, 0x01, 0x01, 0x01, 0x01, 0x01, 0x01, 0x01, 0x01, 0x01, 0x01, 0x01, 0x01, 0x01, 0x01, 0x01, 0x01, 0x01, 0x01, 0x01, 0x01, 0x01, 0x01, 0x01, 0x01, 0x01, 0x01, 0x01, 0x01, 0x01, 0x01, 0x01, 0x01, 0x01, 0x01, 0x01, 0x01, 0x01, 0x01, 0x01, 0x01, 0x01, 0x01, 0x01, 0x01, 0x01, 0x01, 0x01, 0x01, 0x01, 0x01, 0x01, 0x01, 0x01, 0x01, 0x01, 0x00, 0x00, 0x00, 0x00, 0x00, 0x00, 0x00, 0x00, 0x00, 0x00, 0x00, 0x00, 0x00, 0x00, 0x00, 0x00, 0x00, 0x00, 0x00, 0x00, 0x00, 0x00, 0x00, 0x00, 0x00, 0x00, 0x00, 0x00, 0x00, 0x00, 0x00, 0x00, 0x00, 0x00, 0x00, 0x00, 0x00, 0x00, 0x00, 0x00, 0x00, 0x00, 0x00, 0x00, 0x00, 0x00, 0x00, 0x00, 0x00, 0x00, 0x00, 0x00, 0x00, 0x00, 0x00, 0x00, 0x00, 0x00, 0x00, 0x00, 0x00, 0x00, 0x00, 0x00, 0x00, 0x00, 0x00, 0x00, 0x00, 0x00, 0x00, 0x00
};

const char Image1[1024]   ={0x00, 0x00, 0x00, 0x00, 0x00, 0x00, 0x00, 0x00, 0x00, 0x00, 0x00, 0x00, 0x00, 0x00, 0x00, 0x00, 0x00, 0x00, 0x00, 0x00, 0x00, 0x00, 0x00, 0x00, 0x00, 0x00, 0x00, 0x00, 0x00, 0x00, 0x00, 0x00, 0x00, 0x00, 0x00, 0x00, 0x00, 0x00, 0x00, 0x00, 0x00, 0x00, 0x00, 0x00, 0x00, 0x00, 0x80, 0xC0, 0x40, 0x20, 0x20, 0x20, 0x20, 0x20, 0x20, 0x20, 0x20, 0x20, 0x20, 0x10, 0x30, 0x30, 0x30, 0x30, 0x30, 0x30, 0x7E, 0xD1, 0x10, 0x10, 0x20, 0xE0, 0x60, 0x60, 0xE0, 0xE3, 0xFF, 0xDF, 0xFC, 0xFC, 0xFC, 0xF8, 0x78, 0x30, 0x20, 0x60, 0x60, 0xC0, 0x40, 0xC0, 0x40, 0xC0, 0x40, 0xC0, 0x40, 0x40, 0x80, 0xC0, 0x80, 0x80, 0x80, 0x80, 0x80, 0x80, 0x00, 0x00, 0x00, 0x00, 0x00, 0x00, 0x00, 0x00, 0x00, 0x00, 0x00, 0x00, 0x00, 0x00, 0x00, 0x00, 0x00, 0x00, 0x00, 0x00, 0x00, 0x00, 0x00, 0x00,
0x00, 0x00, 0x00, 0x00, 0x00, 0x00, 0x00, 0x00, 0x00, 0x00, 0x00, 0x00, 0x00, 0x00, 0x00, 0x00, 0x00, 0x00, 0x00, 0x00, 0x00, 0x00, 0x00, 0x00, 0x00, 0x00, 0x00, 0x00, 0x00, 0x00, 0x00, 0x00, 0x00, 0x00, 0x00, 0x00, 0x00, 0x00, 0x00, 0x00, 0xFC, 0xFE, 0x36, 0x02, 0x03, 0x01, 0x01, 0x18, 0xF9, 0xC1, 0x03, 0xF7, 0xE6, 0xFE, 0xFC, 0xF8, 0x50, 0x60, 0xE1, 0xC1, 0xC1, 0xC3, 0xF6, 0xDE, 0xC6, 0x04, 0x0C, 0x0C, 0x08, 0x08, 0x18, 0x1F, 0x3C, 0x7E, 0x7F, 0xFF, 0xFF, 0xFF, 0xFF, 0xFF, 0xFF, 0xE7, 0x60, 0x00, 0x00, 0x00, 0x00, 0x00, 0x00, 0x00, 0x00, 0x00, 0x00, 0x00, 0x00, 0x04, 0x00, 0x04, 0x00, 0x00, 0x00, 0x00, 0x01, 0x05, 0x01, 0x03, 0x02, 0x2E, 0x3C, 0xF8, 0xF8, 0xF0, 0xE0, 0xE0, 0xE0, 0xC0, 0xC0, 0x80, 0x00, 0x00, 0x00, 0x00, 0x00, 0x00, 0x00, 0x00, 0x00, 0x00,
0x00, 0x00, 0x18, 0x38, 0x78, 0x78, 0xF8, 0xF8, 0xF8, 0xE8, 0xE0, 0xE0, 0xC0, 0xC0, 0xC0, 0x80, 0x80, 0x00, 0x00, 0x00, 0x00, 0x00, 0x00, 0x00, 0x00, 0x00, 0x00, 0x00, 0x00, 0x00, 0x00, 0x00, 0x00, 0x00, 0x00, 0x00, 0x00, 0x80, 0xC0, 0xF0, 0xFF, 0xFF, 0xF8, 0x40, 0x00, 0x00, 0x00, 0x06, 0x03, 0x00, 0x12, 0x0F, 0xDF, 0xE7, 0xFE, 0x0F, 0x03, 0x00, 0x00, 0x00, 0x03, 0x0D, 0x9F, 0xBF, 0xFF, 0x7F, 0xE0, 0x71, 0x2F, 0x13, 0x11, 0x12, 0x30, 0x9E, 0x9E, 0xFC, 0xF8, 0xFB, 0xFF, 0xFC, 0xFE, 0x9A, 0x32, 0x62, 0x80, 0x00, 0x00, 0x00, 0x00, 0x00, 0x00, 0x00, 0x00, 0x00, 0x00, 0x00, 0x00, 0x00, 0x00, 0x00, 0x00, 0x00, 0x00, 0x00, 0x00, 0x00, 0x00, 0x00, 0x00, 0x01, 0x07, 0xDF, 0xFF, 0xFF, 0xFF, 0xFF, 0xFD, 0xB3, 0x47, 0xFE, 0xFC, 0xF0, 0x00, 0x00, 0x00, 0x00, 0x00, 0x00,
0x00, 0x00, 0x00, 0x00, 0x00, 0x00, 0x00, 0x01, 0x05, 0x05, 0x15, 0x37, 0x37, 0x77, 0xF7, 0xEF, 0xEF, 0xFF, 0xFF, 0xEF, 0xFF, 0xDE, 0xFE, 0xFC, 0xFC, 0xF8, 0xF0, 0xF0, 0xE0, 0x60, 0x20, 0x00, 0x10, 0x08, 0x44, 0x42, 0xD9, 0xB7, 0xEF, 0xFF, 0xFF, 0xFF, 0xFF, 0x81, 0x00, 0x38, 0x78, 0x3C, 0x1C, 0x0E, 0x06, 0x02, 0x03, 0x01, 0x00, 0x00, 0x00, 0x00, 0x02, 0x03, 0x01, 0x01, 0x81, 0x80, 0x80, 0xFC, 0xC3, 0xE0, 0x70, 0x08, 0xFE, 0xFF, 0x83, 0x78, 0xFE, 0xFF, 0xFF, 0xFF, 0xFF, 0xFF, 0xFF, 0xFF, 0xFE, 0x78, 0x00, 0x00, 0x00, 0x00, 0x00, 0x00, 0x00, 0x00, 0x00, 0x00, 0x00, 0x00, 0x00, 0x00, 0x00, 0x00, 0x00, 0x00, 0x00, 0x00, 0x00, 0x00, 0x00, 0x00, 0x00, 0x00, 0x00, 0x00, 0xFF, 0xFF, 0xFF, 0xFF, 0xFF, 0xFD, 0xFE, 0xF9, 0xDF, 0xFF, 0xFF, 0x00, 0x00, 0x00, 0x00, 0x00,
0x00, 0x40, 0x80, 0x80, 0xC0, 0xE4, 0xEC, 0xFC, 0xFC, 0xFE, 0xFC, 0xFC, 0xFC, 0xFC, 0xFC, 0xF8, 0xF9, 0xF9, 0xFD, 0xFF, 0xF7, 0xE7, 0xE5, 0xC7, 0xC3, 0x83, 0x83, 0x81, 0x01, 0x02, 0x04, 0x0C, 0x18, 0x10, 0x30, 0x60, 0xC0, 0x80, 0x00, 0x01, 0x03, 0x07, 0x1F, 0x1F, 0x7F, 0x7C, 0xF8, 0xF8, 0xF8, 0x70, 0x60, 0x60, 0x60, 0x40, 0x00, 0x00, 0x08, 0x00, 0x80, 0x10, 0x40, 0x70, 0xD0, 0xD8, 0xD9, 0xFF, 0xF1, 0xE1, 0xC0, 0x80, 0x80, 0x01, 0x03, 0x1F, 0x0F, 0xF3, 0xFD, 0x1F, 0x0F, 0x07, 0x03, 0x01, 0x00, 0x00, 0x00, 0x00, 0x00, 0x00, 0x00, 0x00, 0x10, 0xC0, 0x24, 0xD8, 0x60, 0xC0, 0x00, 0x00, 0x00, 0x00, 0x00, 0x00, 0x00, 0x00, 0x00, 0x00, 0x00, 0x00, 0x00, 0x00, 0x00, 0x1E, 0xFF, 0xF7, 0xFF, 0xFF, 0xFF, 0xFF, 0xFF, 0xFF, 0xFF, 0xFF, 0x3F, 0x00, 0x00, 0x00, 0x00, 0x00,
0x00, 0x00, 0x00, 0x00, 0x01, 0x03, 0x07, 0x0F, 0x0B, 0x7F, 0xF7, 0xFF, 0xFF, 0xFF, 0xFF, 0xFF, 0xFF, 0xFF, 0xFF, 0xFF, 0xFF, 0xFF, 0xFF, 0xFF, 0xFF, 0xFF, 0xFF, 0xFF, 0xFF, 0xFF, 0xFE, 0xFE, 0xFC, 0xFC, 0xFC, 0xF8, 0xF0, 0xF1, 0xE3, 0xE6, 0xC4, 0x8C, 0x98, 0x30, 0x60, 0xC0, 0xC0, 0xC3, 0x8F, 0xBF, 0xBE, 0xFC, 0x70, 0x70, 0xE0, 0xE0, 0xE0, 0xC0, 0x40, 0x00, 0x00, 0x00, 0x00, 0x01, 0x03, 0x07, 0x0F, 0x0B, 0x18, 0x02, 0x01, 0x01, 0x01, 0x02, 0xBF, 0xF9, 0x80, 0x80, 0x80, 0x80, 0x80, 0xC0, 0xC0, 0xE0, 0xE0, 0xE0, 0xE0, 0xE4, 0xC0, 0xC0, 0xC0, 0x80, 0x01, 0x02, 0x05, 0x06, 0x1D, 0x3F, 0xC4, 0xB4, 0xC9, 0x10, 0x02, 0x00, 0x00, 0x00, 0x00, 0x00, 0x00, 0x00, 0x00, 0x00, 0xFF, 0xFF, 0xFF, 0xFF, 0xFF, 0xFF, 0xFF, 0x7F, 0x1F, 0x03, 0x00, 0x00, 0x00, 0x00, 0x00, 0x00,
0x10, 0x10, 0x10, 0x20, 0x30, 0x70, 0x70, 0x70, 0x70, 0x20, 0x00, 0x00, 0x01, 0x01, 0x07, 0x17, 0x2F, 0x6F, 0xFF, 0xFF, 0xFF, 0xFF, 0xFF, 0xFF, 0xFF, 0xFF, 0xFF, 0xFF, 0xFF, 0xFF, 0xFF, 0xFF, 0xFF, 0xFF, 0xFF, 0xFF, 0xFF, 0xFF, 0xFF, 0xFF, 0xFF, 0x3F, 0x07, 0x03, 0x01, 0x00, 0x00, 0x00, 0x00, 0x01, 0x01, 0x03, 0x03, 0x07, 0x0F, 0x0F, 0x1E, 0x38, 0x40, 0xC0, 0x90, 0x20, 0x43, 0xFF, 0xFF, 0x76, 0xE6, 0x42, 0xC0, 0x64, 0x74, 0x0C, 0x18, 0x30, 0xC7, 0x9F, 0x7F, 0xFF, 0xFF, 0xFF, 0xFF, 0xFF, 0xFF, 0xFF, 0xFF, 0xFF, 0xFF, 0xFF, 0xFF, 0xFF, 0xFF, 0xFF, 0xFF, 0xFE, 0xFC, 0xF8, 0xF8, 0xF0, 0xF0, 0xE1, 0xE7, 0xE7, 0xEF, 0xFE, 0xF8, 0xF8, 0xFA, 0xFE, 0xFC, 0xF8, 0xFF, 0xFE, 0xFC, 0xFF, 0xFF, 0xBF, 0x0F, 0x07, 0x01, 0x00, 0x00, 0x00, 0x00, 0x00, 0x00, 0x00, 0x00, 0x00,
0x00, 0x00, 0x00, 0x00, 0x00, 0x00, 0x00, 0x00, 0x00, 0x00, 0x00, 0x00, 0x00, 0x00, 0x00, 0x00, 0x00, 0x00, 0x00, 0x05, 0x0B, 0x13, 0x37, 0x2F, 0x6F, 0x5F, 0xBF, 0x7F, 0xFF, 0xFF, 0xFF, 0xFF, 0xFF, 0xFF, 0xFF, 0xFF, 0x7F, 0x3F, 0x0F, 0x03, 0x00, 0x00, 0x00, 0x00, 0x00, 0x00, 0x00, 0x00, 0x00, 0x00, 0x00, 0x00, 0x00, 0x00, 0x00, 0x00, 0x00, 0x00, 0x00, 0x00, 0x01, 0x01, 0x02, 0x02, 0x05, 0x05, 0x05, 0x09, 0x08, 0x08, 0x08, 0x0C, 0x1C, 0x14, 0x1F, 0x3B, 0x3C, 0x3F, 0x7F, 0x7F, 0xFF, 0xFF, 0xFF, 0xFF, 0xFF, 0xFF, 0xFF, 0xFF, 0xFF, 0xFF, 0xFF, 0xFF, 0xFF, 0xFF, 0xFF, 0xFF, 0xEF, 0xFF, 0xFF, 0xFF, 0xFF, 0xFF, 0xFF, 0xFF, 0xFF, 0x7F, 0x3F, 0x1F, 0x0F, 0x0F, 0x07, 0x07, 0x01, 0x01, 0x00, 0x00, 0x00, 0x00, 0x00, 0x00, 0x00, 0x00, 0x00, 0x00, 0x00, 0x00, 0x00, 0x00
};

const char Image2[1024] ={0x00, 0x00, 0xC0, 0xB8, 0x4A, 0xB5, 0xD5, 0x7A, 0xAD, 0xFA, 0xCF, 0xFD, 0xEE, 0xFF, 0xFF, 0xFF, 0xFF, 0xFF, 0xFF, 0xFF, 0xFF, 0xFF, 0xFB, 0xBE, 0xF5, 0xAB, 0xFF, 0xDF, 0xFF, 0xFF, 0xFF, 0xFF, 0xFF, 0xFF, 0xFF, 0xFF, 0xFF, 0xFF, 0x7F, 0xFF, 0x6F, 0xFF, 0xBD, 0xF7, 0xEF, 0xBB, 0xEF, 0xDB, 0xBF, 0xEE, 0x7F, 0xDD, 0x7A, 0xF5, 0xE9, 0xD6, 0xEC, 0xA8, 0x50, 0xB0, 0x40, 0xC0, 0x00, 0x00, 0x00, 0x00, 0x00, 0x00, 0x00, 0x00, 0x00, 0x00, 0x00, 0x00, 0x00, 0x00, 0x00, 0x00, 0x00, 0x00, 0x00, 0x00, 0x00, 0x00, 0x00, 0x00, 0x00, 0x00, 0x00, 0x00, 0x00, 0x00, 0x00, 0x00, 0x00, 0x00, 0x00, 0x00, 0x00, 0x00, 0x00, 0x00, 0x00, 0x00, 0x00, 0x00, 0x00, 0x00, 0x00, 0x00, 0x00, 0x00, 0x00, 0x00, 0x00, 0x00, 0x00, 0x00, 0x00, 0x00, 0x00, 0x00, 0x00, 0x00, 0x00, 0x00, 0x00, 0x00,
0x80, 0xBA, 0xE5, 0xFA, 0xDF, 0xF5, 0x7A, 0xDF, 0xF6, 0x5B, 0xEF, 0xBD, 0xEF, 0x7F, 0xFF, 0xFF, 0xDF, 0xFF, 0xFF, 0x7F, 0x5F, 0x1F, 0x57, 0x07, 0x15, 0x07, 0x01, 0x07, 0x01, 0x06, 0x0B, 0x07, 0x0F, 0x17, 0x0F, 0x2F, 0x5F, 0x3F, 0xDF, 0xBF, 0xFD, 0xB7, 0xFD, 0xEE, 0xFF, 0xBD, 0xF6, 0xFB, 0xEF, 0xFE, 0xBB, 0xFF, 0xF5, 0xDF, 0xAE, 0xFF, 0xBB, 0xEF, 0xFB, 0xDE, 0x75, 0xDE, 0x75, 0xDB, 0xB4, 0xEC, 0x50, 0xA8, 0x50, 0xA0, 0x40, 0x80, 0x80, 0x00, 0x00, 0x00, 0x00, 0x00, 0x00, 0x00, 0x00, 0x00, 0x00, 0x00, 0x00, 0x00, 0x00, 0x00, 0x00, 0x00, 0x00, 0x00, 0x00, 0x00, 0x00, 0x00, 0x00, 0x00, 0x00, 0x00, 0x00, 0x00, 0x00, 0x00, 0x00, 0x00, 0x00, 0x00, 0x00, 0x00, 0x00, 0x00, 0x00, 0x00, 0x00, 0x00, 0x00, 0x00, 0x00, 0x00, 0x00, 0x00, 0x00, 0x00, 0x00, 0x00, 0x00, 0x00,
0x00, 0xBE, 0xFF, 0xFE, 0xFF, 0xDB, 0xFF, 0xFA, 0xFF, 0xFF, 0x7F, 0xD7, 0x3D, 0xEB, 0x5E, 0xE3, 0x3C, 0x17, 0x01, 0x00, 0x01, 0x00, 0x00, 0x00, 0x00, 0x00, 0x00, 0x00, 0x00, 0x00, 0x00, 0x00, 0x00, 0x00, 0x00, 0x00, 0x80, 0x00, 0x00, 0x02, 0x00, 0x0B, 0x05, 0x2A, 0x9F, 0x37, 0xAE, 0x7B, 0xDF, 0xFF, 0xFF, 0xFE, 0xFB, 0xDF, 0xFF, 0xFE, 0xFB, 0xFE, 0xFB, 0xEF, 0xFF, 0xBD, 0xFB, 0xFF, 0xFE, 0xDF, 0xF5, 0xFF, 0xF5, 0xEE, 0xFD, 0xD6, 0xFA, 0xF5, 0xF5, 0xEA, 0xE8, 0xD4, 0xD4, 0xA8, 0xD0, 0xA8, 0x50, 0xE0, 0x50, 0xA0, 0xA0, 0xE0, 0xA0, 0xA0, 0xC0, 0x60, 0x80, 0xC0, 0x00, 0x80, 0x00, 0x00, 0x00, 0x00, 0x00, 0x00, 0x00, 0x00, 0x00, 0x00, 0x00, 0x00, 0x00, 0x00, 0x00, 0x00, 0x00, 0x00, 0x00, 0x00, 0x00, 0x00, 0x00, 0x00, 0x00, 0x00, 0x00, 0x00, 0x00, 0x00, 0x00, 0x00,
0x00, 0x02, 0xBF, 0xFF, 0xFF, 0xFE, 0xFF, 0xFF, 0xFF, 0xFF, 0xFF, 0xD5, 0xAA, 0xFF, 0x85, 0xDA, 0xC5, 0x00, 0x80, 0x00, 0x00, 0x00, 0x00, 0x00, 0x00, 0x00, 0x00, 0x00, 0x00, 0x00, 0x28, 0x08, 0xAC, 0x26, 0x52, 0x09, 0x14, 0x08, 0x3E, 0x94, 0x86, 0x64, 0x0C, 0x0C, 0x0A, 0x14, 0x03, 0x0C, 0x12, 0x43, 0x0F, 0xBF, 0xFF, 0xFF, 0xFF, 0xFF, 0xFF, 0xFF, 0xFF, 0xFF, 0xFF, 0xFF, 0xFE, 0xFB, 0xFF, 0xFF, 0xFF, 0xFF, 0xFF, 0xFF, 0xFF, 0xFF, 0xFF, 0xFE, 0xFF, 0xFF, 0xFF, 0xFF, 0xFF, 0xFF, 0xFF, 0xFF, 0x7F, 0xFF, 0x7F, 0xBF, 0xBE, 0x5F, 0x3E, 0x1F, 0x5E, 0x1F, 0x1D, 0x3E, 0x17, 0x1E, 0x16, 0x1B, 0x1E, 0x00, 0x00, 0x00, 0x00, 0x00, 0x00, 0x00, 0x00, 0x00, 0x00, 0x00, 0x00, 0x00, 0x00, 0x00, 0x00, 0x00, 0x00, 0x00, 0x00, 0x00, 0x00, 0x00, 0x00, 0x00, 0x00, 0x00, 0x00, 0x00,
0x00, 0x00, 0x00, 0x0F, 0xFF, 0xFF, 0xFF, 0xFF, 0xFF, 0xFF, 0xFF, 0xFD, 0xFF, 0xAE, 0x5C, 0x1E, 0x36, 0x27, 0x46, 0x4B, 0x2F, 0x02, 0x25, 0x10, 0x02, 0x00, 0x00, 0x00, 0x00, 0x00, 0x00, 0x00, 0x00, 0x00, 0x00, 0x00, 0x00, 0x01, 0x00, 0x00, 0x00, 0x00, 0x00, 0x00, 0x00, 0x40, 0x00, 0x00, 0xA2, 0x09, 0x54, 0x00, 0xAB, 0x2F, 0xBF, 0xFF, 0xFF, 0xFF, 0xFF, 0xFF, 0xFF, 0xFF, 0xFF, 0xFF, 0xFF, 0xFF, 0xFF, 0xFF, 0xFF, 0xFF, 0xFF, 0xFF, 0xFF, 0xDB, 0xEF, 0xFF, 0xFF, 0x7F, 0xDF, 0x5F, 0xBF, 0x5F, 0x3F, 0x57, 0x4F, 0x5F, 0x0E, 0x1F, 0x1F, 0x2D, 0x1E, 0x56, 0x1C, 0x2C, 0x54, 0x08, 0x28, 0x08, 0x20, 0x00, 0x00, 0x00, 0x00, 0x00, 0x00, 0x00, 0x00, 0x00, 0x00, 0x00, 0x00, 0x00, 0x00, 0x00, 0x00, 0x00, 0x00, 0x00, 0x00, 0x00, 0x00, 0x00, 0x00, 0x00, 0x00, 0x00, 0x00, 0x00,
0x00, 0x00, 0x00, 0x00, 0x00, 0x2F, 0xBF, 0xFF, 0xFF, 0xFF, 0xFF, 0xFF, 0xFF, 0xFF, 0xFE, 0xFD, 0xF0, 0xC0, 0xC0, 0x00, 0x00, 0x00, 0x00, 0x00, 0x00, 0x00, 0x00, 0x00, 0x00, 0x00, 0x00, 0x00, 0x00, 0x80, 0x00, 0x00, 0x00, 0x24, 0x00, 0x2A, 0x00, 0x00, 0x08, 0x01, 0x00, 0x00, 0x02, 0x40, 0x0A, 0x80, 0x55, 0x00, 0xAA, 0xA0, 0xFA, 0xFF, 0xFF, 0xFF, 0xFF, 0xFF, 0xFF, 0xFF, 0xFF, 0xFF, 0xFF, 0xFF, 0xFF, 0xFF, 0xFF, 0xFF, 0x5F, 0x97, 0xF5, 0x6F, 0xBF, 0x57, 0x3F, 0xAF, 0x1D, 0x75, 0x16, 0xA8, 0x42, 0x14, 0x40, 0x08, 0x00, 0x01, 0x00, 0x00, 0x00, 0x00, 0x00, 0x00, 0x00, 0x00, 0x00, 0x00, 0x00, 0x00, 0x00, 0x00, 0x00, 0x00, 0x00, 0x00, 0x00, 0x00, 0x00, 0x00, 0x00, 0x00, 0x00, 0x00, 0x00, 0x00, 0x00, 0x00, 0x00, 0x00, 0x00, 0x00, 0x00, 0x00, 0x00, 0x00, 0x00, 0x00,
0x00, 0x00, 0x00, 0x00, 0x00, 0x00, 0x01, 0x07, 0xFF, 0xFF, 0xFF, 0xFF, 0xFF, 0xFF, 0xFF, 0xFF, 0xFF, 0xFF, 0xFF, 0xFF, 0xFE, 0xFC, 0xF8, 0xF0, 0xE0, 0xC0, 0xC0, 0x80, 0x00, 0x00, 0x20, 0x20, 0xA0, 0x32, 0xA0, 0x39, 0xA8, 0x98, 0x5C, 0xD8, 0x4C, 0xA0, 0x56, 0x00, 0x2A, 0x01, 0xA8, 0x02, 0xA8, 0xE4, 0x69, 0xB4, 0x2E, 0xAF, 0x5F, 0xBF, 0xBF, 0x7F, 0xFF, 0x7F, 0xFF, 0xFF, 0xFF, 0xFF, 0xFF, 0xFF, 0xFF, 0xAF, 0x7B, 0x0F, 0xAF, 0x1A, 0xB5, 0x62, 0xC9, 0x84, 0x21, 0x04, 0x11, 0x00, 0x04, 0x00, 0x00, 0x00, 0x00, 0x00, 0x00, 0x00, 0x00, 0x00, 0x00, 0x00, 0x00, 0x00, 0x00, 0x00, 0x00, 0x00, 0x00, 0x00, 0x00, 0x00, 0x00, 0x00, 0x00, 0x00, 0x00, 0x00, 0x00, 0x00, 0x00, 0x00, 0x00, 0x00, 0x00, 0x00, 0x00, 0x00, 0x00, 0x00, 0x00, 0x00, 0x00, 0x00, 0x00, 0x00, 0x00, 0x00,
0x00, 0x00, 0x00, 0x00, 0x00, 0x00, 0x00, 0x00, 0x00, 0x03, 0x3F, 0xFF, 0xFF, 0xFF, 0xFF, 0xFF, 0xFF, 0xFF, 0xFF, 0xFF, 0xFF, 0xFF, 0xFF, 0xFF, 0xFF, 0xFF, 0xFF, 0xFF, 0xFF, 0xFF, 0xFE, 0xFC, 0xFC, 0xF8, 0xF8, 0xF1, 0xE0, 0xF2, 0xE1, 0xE8, 0x62, 0x68, 0x31, 0xA8, 0xE8, 0xBA, 0xEC, 0xD6, 0x6F, 0xAB, 0xB5, 0xAA, 0xF5, 0xAA, 0x55, 0xAA, 0x6A, 0xDA, 0xA5, 0x5A, 0xED, 0xF6, 0xFF, 0xFF, 0xFF, 0xFF, 0xFF, 0x5C, 0x01, 0xAA, 0x04, 0x40, 0x12, 0x00, 0x04, 0x80, 0x11, 0x02, 0x01, 0x00, 0x00, 0x00, 0x00, 0x00, 0x00, 0x00, 0x00, 0x00, 0x00, 0x00, 0x00, 0x00, 0x00, 0x00, 0x00, 0x00, 0x00, 0x00, 0x80, 0x00, 0x00, 0x00, 0x00, 0x00, 0x00, 0x00, 0x00, 0x00, 0x00, 0x00, 0x00, 0x00, 0x00, 0x00, 0x00, 0x00, 0x00, 0x00, 0x00, 0x00, 0x00, 0x00, 0x00, 0x00, 0x00, 0x00, 0x00, 0x00
};

const char Image3[1024]   ={0x00, 0x00, 0x00, 0x00, 0xC0, 0xD0, 0x80, 0x80, 0x80, 0x80, 0x40, 0x40, 0x00, 0x40, 0x60, 0x80, 0x80, 0x80, 0x00, 0x00, 0x00, 0x80, 0x00, 0x00, 0x80, 0x80, 0x00, 0x80, 0x80, 0x00, 0x80, 0x80, 0xC0, 0xC0, 0x00, 0x00, 0x00, 0x80, 0x80, 0xC0, 0x40, 0x60, 0x20, 0x00, 0x00, 0x00, 0x00, 0x00, 0x00, 0x00, 0x00, 0x00, 0x00, 0x00, 0x00, 0x38, 0xEC, 0xEC, 0x7C, 0x18, 0x00, 0x00, 0x00, 0x00, 0x7E, 0xFF, 0xFC, 0xE0, 0x00, 0x00, 0x00, 0x00, 0x00, 0x00, 0x00, 0x00, 0x00, 0x00, 0x00, 0x00, 0x00, 0x00, 0x00, 0x00, 0x00, 0x00,0x00, 0x00, 0x00, 0x00, 0x00, 0x00, 0x00, 0x00, 0x00, 0x00, 0x00, 0x00, 0x00, 0x00, 0x00, 0x00, 0x00, 0x00, 0x00, 0x00, 0x00, 0x00, 0x00, 0x00, 0x00, 0x00, 0x00, 0x00, 0x00, 0x00, 0x00, 0x00, 0x00, 0x00, 0x00, 0x00, 0x00, 0x00, 0x00, 0x00, 0x00, 0x00,
0x70, 0x04, 0x02, 0x13, 0x10, 0x08, 0x00, 0x0C, 0x0E, 0x0C, 0x04, 0x0C, 0x20, 0x22, 0x33, 0x13, 0x0B, 0x05, 0x06, 0x06, 0x04, 0x07, 0x1E, 0xF7, 0x70, 0x38, 0x3C, 0x33, 0x12, 0x09, 0x0D, 0x05, 0x06, 0x06, 0x02, 0x03, 0x01, 0x00, 0x00, 0x00, 0x00, 0x00, 0x00, 0x80, 0x20, 0x10, 0x10, 0x10, 0x18, 0x08, 0x04, 0x04, 0x06, 0x02, 0x03, 0x01, 0x00, 0x40, 0x10, 0x00, 0x00, 0x00, 0x00, 0x00, 0x00, 0x2F, 0xFF, 0xFF, 0xE8, 0x00, 0x00, 0x00, 0x00, 0x00, 0x00, 0x00, 0x00, 0x80, 0x80, 0xC0, 0x40, 0x40, 0x60, 0x20, 0x30, 0x10, 0x00, 0x00, 0x00, 0x00, 0x00, 0x00, 0x00, 0x00, 0x00, 0x00, 0x00, 0x00, 0x00, 0x00, 0x00, 0x00, 0x00, 0x00, 0x00, 0x00, 0x00, 0x00, 0x00, 0x00, 0x00, 0x00, 0x00, 0x00, 0x00, 0x00, 0x00, 0x00, 0x00, 0x00, 0x00, 0x00, 0x00, 0x00, 0x00, 0x00, 0x00, 0x00,
0x01, 0x00, 0x00, 0x00, 0x00, 0x00, 0x00, 0x00, 0x00, 0x00, 0x50, 0x00, 0x00, 0x00, 0x00, 0x00, 0x00, 0x00, 0x0A, 0x3F, 0x7E, 0xF8, 0xF0, 0x80, 0x00, 0x00, 0x10, 0x38, 0xE0, 0x00, 0x00, 0x80, 0xF0, 0xC0, 0xB8, 0xE0, 0xC0, 0x00, 0x00, 0x00, 0x1E, 0x7F, 0xE7, 0xC7, 0x87, 0x8F, 0x8F, 0x9F, 0xDE, 0xFC, 0xFC, 0xF8, 0x30, 0x00, 0x00, 0x00, 0x16, 0x31, 0x20, 0x30, 0x00, 0xC0, 0x40, 0x60, 0x30, 0x30, 0x3F, 0xFF, 0xFF, 0x8C, 0x0C, 0x04, 0x06, 0x02, 0x03, 0x03, 0x41, 0xF9, 0x00, 0x00, 0x00, 0x00, 0x00, 0x00, 0x00, 0x00, 0x00, 0x00, 0x00, 0x00, 0x00, 0x00, 0x00, 0x00, 0x00, 0x00, 0x00, 0x00, 0x00, 0x00, 0x00, 0x00, 0x00, 0x00, 0x00, 0x00, 0x00, 0x00, 0x00, 0x00, 0x00, 0x00, 0x00, 0x00, 0x00, 0x00, 0x00, 0x00, 0x00, 0x00, 0x00, 0x00, 0x00, 0x00, 0x00, 0x00, 0x00, 0x00,
0x00, 0x00, 0x00, 0x00, 0x00, 0x00, 0x80, 0x80, 0x80, 0x9F, 0x18, 0x30, 0x30, 0x00, 0x00, 0x40, 0x60, 0xC0, 0x40, 0x00, 0x00, 0x03, 0x0F, 0x7F, 0xFE, 0xF0, 0xC0, 0x00, 0x01, 0x03, 0x81, 0xC3, 0xC0, 0xE0, 0xF1, 0xF1, 0xF8, 0xB8, 0xBC, 0x9C, 0x9E, 0x9E, 0x8F, 0x8F, 0x87, 0xC7, 0x87, 0x83, 0xC1, 0x81, 0xC0, 0xC0, 0xC0, 0x80, 0xC0, 0xC0, 0xC0, 0xC0, 0xC0, 0xC0, 0xC0, 0xC0, 0xC0, 0xC0, 0xC0, 0xC0, 0xC0, 0xFF, 0xFF, 0xFF, 0x80, 0x00, 0x00, 0x00, 0x00, 0x68, 0x63, 0x44, 0xCA, 0x59, 0x59, 0x00, 0x00, 0x00, 0x00, 0x00, 0x00, 0x00, 0x00, 0x00, 0x00, 0x00, 0x00, 0x00, 0x00, 0x00, 0x00, 0x00, 0x00, 0x00, 0x00, 0x00, 0x00, 0x00, 0x00, 0x00, 0x00, 0x00, 0x00, 0x00, 0x00, 0x00, 0x00, 0x00, 0x00, 0x00, 0x00, 0x00, 0x00, 0x00, 0x00, 0x00, 0x00, 0x00, 0x00, 0x00, 0x00, 0x00,
0x00, 0x00, 0x00, 0x00, 0x00, 0xC0, 0x60, 0x01, 0x03, 0x03, 0x03, 0x06, 0x3C, 0x60, 0x32, 0x02, 0x00, 0x00, 0x00, 0x00, 0x00, 0x80, 0xC0, 0xE0, 0xF7, 0x7F, 0x1F, 0x3E, 0x78, 0xF0, 0xE7, 0xC7, 0x87, 0x03, 0x07, 0x07, 0x03, 0x07, 0x03, 0x07, 0x03, 0x03, 0x03, 0x83, 0xC3, 0xE3, 0xF3, 0xF3, 0x7B, 0x3B, 0x3B, 0x3F, 0x1F, 0x1F, 0x1F, 0x1F, 0x0F, 0x0F, 0x0F, 0x0F, 0x07, 0x07, 0x03, 0x03, 0x03, 0x03, 0x00, 0x02, 0x7F, 0xFF, 0xFD, 0x80, 0x00, 0x00, 0x00, 0x00, 0x00, 0x00, 0x00, 0x00, 0x0E, 0x1E, 0x3C, 0xF8, 0xF0, 0x80, 0x00, 0x00, 0x00, 0x00, 0x00, 0x00, 0x00, 0x00, 0x00, 0x00, 0x00, 0x00, 0x00, 0x00, 0x00, 0x00, 0x00, 0x00, 0x00, 0x00, 0x00, 0x00, 0x00, 0x00, 0x00, 0x00, 0x00, 0x00, 0x00, 0x00, 0x00, 0x00, 0x00, 0x00, 0x00, 0x00, 0x00, 0x00, 0x00, 0x00, 0x00, 0x00,
0x00, 0x00, 0x00, 0xF8, 0xDF, 0x81, 0x00, 0x00, 0x80, 0x80, 0x80, 0xC0, 0xC0, 0xE0, 0xE0, 0xF0, 0xF8, 0x78, 0x3C, 0x1E, 0x0F, 0x07, 0x07, 0x01, 0x00, 0x00, 0x00, 0x00, 0x00, 0x00, 0x01, 0x83, 0xC7, 0xC7, 0x0E, 0x1E, 0x1C, 0x3C, 0x38, 0x78, 0x70, 0xF0, 0xFC, 0xFF, 0xFB, 0xF1, 0xE0, 0xE0, 0xE0, 0xE0, 0xC0, 0x00, 0x00, 0x00, 0x00, 0x00, 0x00, 0x00, 0x80, 0xC0, 0x00, 0x00, 0x00, 0x00, 0x00, 0x00, 0x00, 0x00, 0x01, 0x0F, 0x3F, 0x7E, 0x78, 0xF0, 0xF0, 0xE0, 0xE0, 0xE0, 0xE0, 0xE0, 0x70, 0x70, 0x38, 0x38, 0x0F, 0x02, 0x00, 0x00, 0x00, 0x00, 0x00, 0x00, 0x00, 0x00, 0x00, 0x00, 0x00, 0x00, 0x00, 0x00, 0x00, 0x00, 0x00, 0x00, 0x00, 0x00, 0x00, 0x00, 0x00, 0x00, 0x00, 0x00, 0x00, 0x00, 0x00, 0x00, 0x00, 0x00, 0x00, 0x00, 0x00, 0x00, 0x00, 0x00, 0x00, 0x00, 0x00, 0x00,
0x00, 0x00, 0x00, 0x00, 0x03, 0x07, 0x07, 0x07, 0x07, 0x07, 0x07, 0x07, 0x03, 0x03, 0x01, 0x00, 0x00, 0x00, 0x00, 0x00, 0x30, 0x10, 0x10, 0x10, 0x18, 0x08, 0x08, 0x0C, 0x04, 0x02, 0x03, 0x01, 0x01, 0x01, 0x00, 0x00, 0x00, 0x00, 0x00, 0x00, 0x00, 0x00, 0x00, 0x00, 0x01, 0x01, 0x01, 0x01, 0x03, 0x01, 0x01, 0x00, 0x00, 0x00, 0x00, 0x00, 0x00, 0x1E, 0x19, 0x18, 0x18, 0x08, 0x08, 0x04, 0x04, 0x02, 0x00, 0x00, 0x00, 0x00, 0x00, 0x00, 0x0E, 0x0E, 0x0F, 0x1E, 0x1E, 0x0C, 0x06, 0x07, 0x0F, 0x1F, 0x0E, 0x0E, 0x04, 0x00, 0x00, 0x00, 0x00, 0x00, 0x00, 0x00, 0x00, 0x00, 0x00, 0x00, 0x00, 0x00, 0x00, 0x00, 0x00, 0x00, 0x00, 0x00, 0x00, 0x00, 0x00, 0x00, 0x00, 0x00, 0x00, 0x00, 0x00, 0x00, 0x00, 0x00, 0x00, 0x00, 0x00, 0x00, 0x00, 0x00, 0x00, 0x00, 0x00, 0x00, 0x00, 0x00,
0x00, 0x00, 0x00, 0x00, 0x00, 0x00, 0x00, 0x00, 0x00, 0x00, 0x00, 0x00, 0x00, 0x00, 0x00, 0x00, 0x00, 0x00, 0x00, 0x00, 0x00, 0x00, 0x00, 0x00, 0x00, 0x00, 0x00, 0x00, 0x00, 0x00, 0x00, 0x00, 0x00, 0x00, 0x00, 0x00, 0x00, 0x00, 0x00, 0x00, 0x00, 0x00, 0x00, 0x00, 0x00, 0x00, 0x00, 0x00, 0x00, 0x00, 0x00, 0x00, 0x00, 0x00, 0x00, 0x00, 0x00, 0x00, 0x00, 0x00, 0x00, 0x00, 0x00, 0x00, 0x00, 0x00, 0x00, 0x00, 0x00, 0x00, 0x00, 0x00, 0x00, 0x00, 0x00, 0x00, 0x00, 0x00, 0x00, 0x00, 0x00, 0x00, 0x00, 0x00, 0x00, 0x00, 0x00, 0x00, 0x00, 0x00, 0x00, 0x00, 0x00, 0x00, 0x00, 0x00, 0x00, 0x00, 0x00, 0x00, 0x00, 0x00, 0x00, 0x00, 0x00, 0x00, 0x00, 0x00, 0x00, 0x00, 0x00, 0x00, 0x00, 0x00, 0x00, 0x00, 0x00, 0x00, 0x00, 0x00, 0x00, 0x00, 0x00, 0x00, 0x00, 0x00, 0x00, 0x00
};

const char Image5[1024]   ={0xFF, 0xFF, 0xFF, 0xFF, 0xFF, 0xFF, 0xFF, 0xFF, 0xFF, 0xFF, 0xFF, 0xFF, 0xFF, 0xFF, 0xFF, 0xFF, 0xFF, 0xFF, 0xFF, 0xFF, 0xFF, 0xFF, 0xFF, 0xFF, 0xFF, 0xFF, 0xFF, 0xFF, 0xFF, 0xFF, 0xFF, 0xFF, 0xFF, 0xFF, 0xFF, 0xFF, 0xFF, 0xFF, 0xFF, 0xFF, 0xFF, 0xFF, 0xFF, 0xFF, 0xFF, 0xFF, 0x7F, 0x7F, 0x3F, 0x3F, 0x3F, 0x3F, 0x3F, 0x5F, 0x9F, 0xDF, 0xDF, 0xFF, 0xFF, 0xFF, 0xFF, 0xFF, 0xFF, 0xFF, 0xFF, 0xFF, 0xFF, 0xFF, 0xFF, 0xFF, 0xFF, 0xFF, 0xFF, 0xFF, 0xFF, 0xFF, 0xFF, 0xFF, 0xFF, 0xFF, 0xFF, 0xFF, 0xFF, 0xFF, 0xFF, 0xFF, 0xFF, 0xFF, 0xFF, 0xFF, 0xFF, 0xFF, 0xFF, 0xFF, 0xFF, 0xFF, 0xFF, 0xFF, 0xFF, 0xFF, 0xFF, 0xFF, 0xFF, 0xFF, 0xFF, 0xFF, 0xFF, 0xFF, 0xFF, 0xFF, 0xFF, 0xFF, 0xFF, 0xFF, 0xFF, 0xFF, 0xFF, 0xFF, 0xFF, 0xFF, 0xFF, 0xFF, 0xFF, 0xFF, 0xFF, 0xFF, 0xFF, 0xFF,
0xCF, 0xEF, 0xF7, 0xF7, 0xFF, 0xFF, 0xFF, 0xFF, 0xFF, 0xFF, 0xFF, 0xFF, 0xFF, 0xFF, 0xFF, 0xFF, 0xFF, 0xFF, 0xFF, 0xFF, 0xFF, 0xFF, 0xFF, 0xFF, 0xFF, 0xFF, 0xFF, 0xFF, 0xFF, 0xFF, 0xFF, 0xFF, 0xFF, 0xFF, 0xFF, 0xFF, 0x7F, 0x1F, 0x0F, 0x0F, 0x07, 0x03, 0x01, 0x01, 0x00, 0x00, 0x00, 0x00, 0x84, 0x87, 0xA2, 0x62, 0x5A, 0x65, 0xB5, 0x77, 0xF7, 0xFB, 0x7B, 0x7F, 0x7F, 0xFF, 0xFF, 0xFF, 0xFF, 0xFF, 0xFF, 0xFF, 0xFF, 0xFF, 0xFF, 0xFF, 0xFF, 0xFF, 0xFF, 0xFF, 0xFF, 0xFF, 0xFF, 0xFF, 0xFF, 0xFF, 0xFF, 0xFF, 0xFF, 0xFF, 0xFF, 0xFF, 0xFF, 0xFF, 0xFF, 0xFF, 0xFF, 0xFF, 0xFF, 0xFF, 0xFF, 0xFF, 0xFF, 0xFF, 0xFF, 0xFF, 0xFF, 0xFF, 0xFF, 0xFF, 0xFF, 0xFF, 0xFF, 0xFF, 0xFF, 0xFF, 0xFF, 0xFF, 0xFF, 0xFF, 0xFF, 0xFF, 0xFF, 0xFF, 0xFF, 0xFF, 0xFF, 0xFF, 0xFF, 0xFF, 0xFF, 0xFF,
0xFF, 0xFF, 0xFF, 0xFF, 0xFF, 0xFF, 0xFF, 0xFF, 0xFF, 0xFF, 0xFF, 0xFF, 0xFF, 0xFF, 0xFF, 0xFF, 0xFF, 0xFF, 0xFF, 0xFF, 0xFF, 0xFF, 0xFF, 0xFF, 0xFF, 0xFF, 0xFF, 0xFF, 0xFF, 0xFF, 0xFF, 0xFF, 0xFF, 0xFF, 0x03, 0xE0, 0xE0, 0xE0, 0xE0, 0xE0, 0xE0, 0xE8, 0xE8, 0xE4, 0xE4, 0xF0, 0xF2, 0xC3, 0xC3, 0xC9, 0x44, 0x44, 0x44, 0x43, 0x12, 0x13, 0x19, 0x0C, 0x2C, 0xA4, 0x94, 0x93, 0x1B, 0x1F, 0x6F, 0x77, 0x7F, 0x7F, 0xFF, 0xFF, 0xFF, 0xFF, 0x0F, 0x03, 0x7F, 0xFF, 0xFF, 0xFF, 0xFF, 0xFF, 0xFF, 0xFF, 0xFF, 0xFF, 0xFF, 0xFF, 0xFF, 0xFF, 0xFF, 0xFF, 0xFF, 0xFF, 0xFF, 0xFF, 0xFF, 0xFF, 0xFF, 0xFF, 0xFF, 0xFF, 0xFF, 0xFF, 0xFF, 0xFF, 0xFF, 0xFF, 0xFF, 0xFF, 0xFF, 0xFF, 0xFF, 0xFF, 0xFF, 0xFF, 0xFF, 0xFF, 0xFF, 0xFF, 0xFF, 0xFF, 0xFF, 0xFF, 0xFF, 0xFF, 0xFF, 0xFF, 0xFF, 0xFF,
0xFF, 0xFF, 0xFF, 0xFF, 0xFF, 0xFF, 0xFF, 0xFF, 0xFF, 0xFF, 0xFF, 0xFF, 0xFF, 0xFF, 0xFF, 0xFF, 0xFF, 0xFF, 0xFF, 0xFF, 0xFF, 0xFF, 0xFF, 0xFF, 0xFF, 0xFF, 0xFF, 0xFF, 0xFF, 0xFF, 0xFF, 0xFF, 0xFF, 0xFF, 0xFF, 0xFF, 0xFF, 0xFF, 0xFF, 0xFF, 0xFF, 0xFF, 0xFF, 0xFF, 0xFF, 0xFF, 0xFF, 0xFF, 0xFF, 0xE4, 0x80, 0x80, 0x00, 0x80, 0xC0, 0xC0, 0xC0, 0xC0, 0xC8, 0xD8, 0xD8, 0xDC, 0xDC, 0xDE, 0x9E, 0x9E, 0xBE, 0x3F, 0x3F, 0x3F, 0x7F, 0xFF, 0x00, 0x00, 0x80, 0x00, 0x01, 0x02, 0x07, 0xFF, 0xFF, 0xFF, 0xFF, 0xFF, 0xFF, 0xFF, 0xFF, 0xFF, 0x3F, 0x7F, 0xFF, 0xFF, 0xFF, 0xFF, 0xFF, 0xFF, 0xFF, 0xFF, 0xFF, 0xFF, 0xFF, 0xFF, 0xFF, 0xFF, 0xFF, 0xFF, 0xFF, 0xFF, 0xFF, 0xFF, 0xFF, 0xFF, 0xFF, 0xFF, 0xFF, 0xFF, 0xFF, 0xFF, 0xFF, 0xFF, 0xFF, 0xFF, 0xFF, 0xFF, 0xFF, 0xFF, 0xFF, 0xFF,
0xFF, 0xFF, 0xFF, 0xFF, 0xFF, 0xFF, 0xFF, 0xFF, 0xFF, 0xFF, 0xFF, 0xFF, 0xFF, 0xFF, 0xFF, 0xFF, 0xFF, 0xFF, 0xFF, 0xFF, 0xFF, 0xFF, 0xFF, 0xFF, 0xFF, 0xFF, 0xFF, 0xFF, 0xFF, 0xFF, 0xFF, 0xFF, 0xFF, 0xFF, 0xFF, 0xFF, 0xFF, 0xFF, 0xFF, 0x00, 0x00, 0x01, 0x03, 0x03, 0x03, 0x03, 0x01, 0x1F, 0x07, 0x23, 0x33, 0x7F, 0xFF, 0xFF, 0xFF, 0xFF, 0x7F, 0x3F, 0x1F, 0x0F, 0x07, 0x03, 0x02, 0x06, 0x06, 0x07, 0x0F, 0x0F, 0x1F, 0x0F, 0xFF, 0xFE, 0xFF, 0xFE, 0xFF, 0xFF, 0xFE, 0xFC, 0x18, 0x00, 0x40, 0xF0, 0xFF, 0x7F, 0x3F, 0x1F, 0x07, 0x00, 0x80, 0xC0, 0xFF, 0xFF, 0xFF, 0xFF, 0xFF, 0xFF, 0xFF, 0xFF, 0xFF, 0xFF, 0xFF, 0xFF, 0xFF, 0xFF, 0xFF, 0xFF, 0xFF, 0xFF, 0xFF, 0xFF, 0xFF, 0xFF, 0xFF, 0xFF, 0xFF, 0xFF, 0xFF, 0xFF, 0xFF, 0xFF, 0xFF, 0xFF, 0xFF, 0xFF, 0xFF, 0xFF, 0xFF, 0xFF,
0xFF, 0xFF, 0xFF, 0xFF, 0xFF, 0xFF, 0xFF, 0xFF, 0xFF, 0xFF, 0xFF, 0xFF, 0xFF, 0xFF, 0xFF, 0xFF, 0xFF, 0xFF, 0xFF, 0xFF, 0xFF, 0xFF, 0xFF, 0xFF, 0xFF, 0xFF, 0xFF, 0xFF, 0xFF, 0xFF, 0xFF, 0xFF, 0xFF, 0x7F, 0xBF, 0xFF, 0xFF, 0xFF, 0xFF, 0xF0, 0xC0, 0x80, 0x00, 0x30, 0x70, 0x70, 0x70, 0x70, 0xE0, 0xE0, 0xE0, 0xE0, 0xE2, 0xE7, 0xEB, 0xC3, 0x40, 0x40, 0x00, 0x00, 0x00, 0x00, 0x00, 0x00, 0x00, 0x00, 0x00, 0x00, 0x00, 0x00, 0xFF, 0xFF, 0xFF, 0xFF, 0xCF, 0x07, 0x03, 0x00, 0x00, 0x00, 0x00, 0x80, 0xE0, 0xF0, 0xF8, 0xFC, 0xFE, 0xFE, 0xFF, 0xFF, 0xFF, 0xFF, 0xFF, 0xFF, 0xDF, 0xFF, 0x7F, 0xFF, 0xFF, 0x7F, 0x1F, 0x1E, 0x7C, 0x7D, 0x3F, 0x0F, 0x4F, 0x6F, 0xFF, 0x7F, 0x77, 0xB7, 0xF7, 0xF7, 0xFF, 0xFF, 0xFF, 0xFF, 0xFF, 0xFF, 0xFF, 0xFF, 0xFF, 0xFF, 0xFF, 0xFF, 0xFF, 0xFF,
0xF3, 0xFB, 0xFB, 0xFB, 0xFB, 0xFB, 0x3B, 0xFB, 0xFB, 0xFB, 0xFB, 0x3B, 0xFB, 0xFB, 0xFB, 0xFB, 0xFB, 0xFB, 0xFB, 0xFB, 0xFB, 0x1B, 0xFB, 0xFB, 0x7B, 0xFB, 0xFB, 0xFB, 0xFB, 0xFB, 0xF3, 0x03, 0xF3, 0xA8, 0x5B, 0xAB, 0x5B, 0xAB, 0x5B, 0xAB, 0x5B, 0xAB, 0x58, 0xA8, 0x58, 0xA8, 0x58, 0xA8, 0x58, 0xA8, 0x58, 0xA8, 0x58, 0xA8, 0x58, 0xA8, 0x58, 0xA8, 0x58, 0xA8, 0x58, 0xA8, 0xF0, 0x00, 0xF0, 0xA8, 0x58, 0xA8, 0x5A, 0xAB, 0x5B, 0xAB, 0x5B, 0xAB, 0x58, 0xA8, 0x58, 0xA8, 0x58, 0xAA, 0x5B, 0xAB, 0x5B, 0xAB, 0x5B, 0xAB, 0x5B, 0xAB, 0x5B, 0xAB, 0x5B, 0xAB, 0x5B, 0xAB, 0xF0, 0x01, 0xF3, 0xFB, 0xF8, 0xF8, 0xF8, 0xF8, 0xF8, 0xF8, 0x38, 0xB8, 0xB8, 0xB8, 0xBA, 0xFB, 0xFB, 0xFB, 0xFB, 0xFB, 0xFB, 0xBB, 0xFB, 0xFB, 0x7B, 0xFB, 0xFB, 0xFB, 0xFB, 0xFB, 0xFB, 0xFB, 0xF3, 0x03,
0x7F, 0xFF, 0xFF, 0xFF, 0xFF, 0xFF, 0xF0, 0xEF, 0xEF, 0xEF, 0xEF, 0xF0, 0xFF, 0x80, 0xEE, 0xEE, 0xF1, 0xFF, 0xF1, 0xEE, 0xEE, 0xE0, 0xFF, 0xFE, 0xF0, 0xEE, 0xEE, 0xFF, 0xFF, 0xFF, 0x7F, 0x00, 0x7F, 0xAA, 0xD5, 0xAA, 0xD5, 0xAA, 0xD5, 0xAA, 0xD5, 0xAA, 0xD5, 0xAA, 0xD5, 0xAA, 0xD5, 0xAA, 0xD5, 0xAA, 0xD5, 0xAA, 0xD5, 0xAA, 0xD5, 0xAA, 0xD5, 0xAA, 0xD5, 0xAA, 0xD5, 0xAA, 0x7F, 0x00, 0x7F, 0xAA, 0xD5, 0xAA, 0xD5, 0xAA, 0xD5, 0xAA, 0xD5, 0xAA, 0xD5, 0xAA, 0xD5, 0xAA, 0xD5, 0xAA, 0xD5, 0xAA, 0xD5, 0xAA, 0xD5, 0xAA, 0xD5, 0xAA, 0xD5, 0xAA, 0xD5, 0xAA, 0xD5, 0xAA, 0x7F, 0x00, 0x7F, 0xFF, 0xFF, 0xFF, 0xFF, 0xFF, 0xFF, 0xFF, 0xE0, 0xED, 0xED, 0xED, 0xEF, 0xFF, 0xE4, 0xFB, 0xFB, 0xE4, 0xFF, 0xE0, 0xFF, 0xFE, 0xF0, 0xEE, 0xEE, 0xFF, 0xFF, 0xFF, 0xFF, 0xFF, 0x7F, 0x00
};
/* USER CODE END PV */

void SystemClock_Config(void);
static void MX_GPIO_Init(void);
static void MX_USART2_UART_Init(void);
/* USER CODE BEGIN PFP */

void Data_Write(uint8_t d);
void GLCD_WriteCommand(uint8_t cmd);
void GLCD_WriteData(uint8_t data);
void GLCD_Initialize( void );
void GLCD_PageSelect(uint8_t page_select);
void GLCD_PrintChar(const char *ptr);
void GLCD_SetCursor(uint8_t x, uint8_t y);
void GLCD_CreateImage(const char *image);
void GLCD_WriteString(const char *str);

void GLCD_ClearAll( void );
/* USER CODE END PFP */

int main(void)
{

  /* MCU Configuration--------------------------------------------------------*/

  /* Reset of all peripherals, Initializes the Flash interface and the Systick. */
  HAL_Init();

  /* Configure the system clock */
  SystemClock_Config();

  /* Initialize all configured peripherals */
  MX_GPIO_Init();
  MX_USART2_UART_Init();
  /* USER CODE BEGIN 2 */
  GLCD_Initialize();
  GLCD_ClearAll();
  /* USER CODE END 2 */

  /* Infinite loop */
  /* USER CODE BEGIN WHILE */
  while (1)
  {
//	  GLCD_PageSelect(0);
//	  GLCD_SetCursor(0, 0);
//	  GLCD_WriteString("Adc Value : 2658");
//	  GLCD_PageSelect(1);
//	  GLCD_SetCursor(2, 0);
//	  GLCD_WriteString("Led 1 On");

      GLCD_CreateImage(Image1);
      HAL_Delay(5000);
      GLCD_CreateImage(Image2);
      HAL_Delay(5000);
      GLCD_CreateImage(Image3);
      HAL_Delay(5000);
      GLCD_CreateImage(Image5);
      HAL_Delay(5000);
    /* USER CODE END WHILE */

  }
}

void SystemClock_Config(void)
{
  RCC_OscInitTypeDef RCC_OscInitStruct = {0};
  RCC_ClkInitTypeDef RCC_ClkInitStruct = {0};

  /** Configure the main internal regulator output voltage
  */
  __HAL_RCC_PWR_CLK_ENABLE();
  __HAL_PWR_VOLTAGESCALING_CONFIG(PWR_REGULATOR_VOLTAGE_SCALE3);

  /** Initializes the RCC Oscillators according to the specified parameters
  * in the RCC_OscInitTypeDef structure.
  */
  RCC_OscInitStruct.OscillatorType = RCC_OSCILLATORTYPE_HSI;
  RCC_OscInitStruct.HSIState = RCC_HSI_ON;
  RCC_OscInitStruct.HSICalibrationValue = RCC_HSICALIBRATION_DEFAULT;
  RCC_OscInitStruct.PLL.PLLState = RCC_PLL_ON;
  RCC_OscInitStruct.PLL.PLLSource = RCC_PLLSOURCE_HSI;
  RCC_OscInitStruct.PLL.PLLM = 16;
  RCC_OscInitStruct.PLL.PLLN = 336;
  RCC_OscInitStruct.PLL.PLLP = RCC_PLLP_DIV4;
  RCC_OscInitStruct.PLL.PLLQ = 2;
  RCC_OscInitStruct.PLL.PLLR = 2;
  if (HAL_RCC_OscConfig(&RCC_OscInitStruct) != HAL_OK)
  {
    Error_Handler();
  }

  /** Initializes the CPU, AHB and APB buses clocks
  */
  RCC_ClkInitStruct.ClockType = RCC_CLOCKTYPE_HCLK|RCC_CLOCKTYPE_SYSCLK
                              |RCC_CLOCKTYPE_PCLK1|RCC_CLOCKTYPE_PCLK2;
  RCC_ClkInitStruct.SYSCLKSource = RCC_SYSCLKSOURCE_PLLCLK;
  RCC_ClkInitStruct.AHBCLKDivider = RCC_SYSCLK_DIV1;
  RCC_ClkInitStruct.APB1CLKDivider = RCC_HCLK_DIV2;
  RCC_ClkInitStruct.APB2CLKDivider = RCC_HCLK_DIV1;

  if (HAL_RCC_ClockConfig(&RCC_ClkInitStruct, FLASH_LATENCY_2) != HAL_OK)
  {
    Error_Handler();
  }
}

static void MX_USART2_UART_Init(void)
{

  huart2.Instance = USART2;
  huart2.Init.BaudRate = 115200;
  huart2.Init.WordLength = UART_WORDLENGTH_8B;
  huart2.Init.StopBits = UART_STOPBITS_1;
  huart2.Init.Parity = UART_PARITY_NONE;
  huart2.Init.Mode = UART_MODE_TX_RX;
  huart2.Init.HwFlowCtl = UART_HWCONTROL_NONE;
  huart2.Init.OverSampling = UART_OVERSAMPLING_16;
  if (HAL_UART_Init(&huart2) != HAL_OK)
  {
    Error_Handler();
  }

}

static void MX_GPIO_Init(void)
{
  GPIO_InitTypeDef GPIO_InitStruct = {0};

  /* GPIO Ports Clock Enable */
  __HAL_RCC_GPIOC_CLK_ENABLE();
  __HAL_RCC_GPIOH_CLK_ENABLE();
  __HAL_RCC_GPIOA_CLK_ENABLE();
  __HAL_RCC_GPIOB_CLK_ENABLE();

  /*Configure GPIO pin Output Level */
  HAL_GPIO_WritePin(GPIOC, RS_Pin|RW_Pin|D7_Pin, GPIO_PIN_RESET);

  /*Configure GPIO pin Output Level */
  HAL_GPIO_WritePin(GPIOA, CS2_Pin|CS1_Pin|RST_Pin|LD2_Pin
                          |D5_Pin|D6_Pin|D0_Pin, GPIO_PIN_RESET);

  /*Configure GPIO pin Output Level */
  HAL_GPIO_WritePin(GPIOB, EN_Pin|D4_Pin|D1_Pin|D3_Pin
                          |D2_Pin, GPIO_PIN_RESET);

  /*Configure GPIO pin : B1_Pin */
  GPIO_InitStruct.Pin = B1_Pin;
  GPIO_InitStruct.Mode = GPIO_MODE_IT_FALLING;
  GPIO_InitStruct.Pull = GPIO_NOPULL;
  HAL_GPIO_Init(B1_GPIO_Port, &GPIO_InitStruct);

  /*Configure GPIO pins : RS_Pin RW_Pin D7_Pin */
  GPIO_InitStruct.Pin = RS_Pin|RW_Pin|D7_Pin;
  GPIO_InitStruct.Mode = GPIO_MODE_OUTPUT_PP;
  GPIO_InitStruct.Pull = GPIO_NOPULL;
  GPIO_InitStruct.Speed = GPIO_SPEED_FREQ_LOW;
  HAL_GPIO_Init(GPIOC, &GPIO_InitStruct);

  /*Configure GPIO pins : CS2_Pin CS1_Pin RST_Pin LD2_Pin
                           D5_Pin D6_Pin D0_Pin */
  GPIO_InitStruct.Pin = CS2_Pin|CS1_Pin|RST_Pin|LD2_Pin
                          |D5_Pin|D6_Pin|D0_Pin;
  GPIO_InitStruct.Mode = GPIO_MODE_OUTPUT_PP;
  GPIO_InitStruct.Pull = GPIO_NOPULL;
  GPIO_InitStruct.Speed = GPIO_SPEED_FREQ_LOW;
  HAL_GPIO_Init(GPIOA, &GPIO_InitStruct);

  /*Configure GPIO pins : EN_Pin D4_Pin D1_Pin D3_Pin
                           D2_Pin */
  GPIO_InitStruct.Pin = EN_Pin|D4_Pin|D1_Pin|D3_Pin
                          |D2_Pin;
  GPIO_InitStruct.Mode = GPIO_MODE_OUTPUT_PP;
  GPIO_InitStruct.Pull = GPIO_NOPULL;
  GPIO_InitStruct.Speed = GPIO_SPEED_FREQ_LOW;
  HAL_GPIO_Init(GPIOB, &GPIO_InitStruct);

}

/* USER CODE BEGIN 4 */

void Data_Write(uint8_t d)
{
	Typedef_PinConfig y = (Typedef_PinConfig)d;

	HAL_GPIO_WritePin(D0_GPIO_Port, D0_Pin, y.b0);
	HAL_GPIO_WritePin(D1_GPIO_Port, D1_Pin, y.b1);
	HAL_GPIO_WritePin(D2_GPIO_Port, D2_Pin, y.b2);
	HAL_GPIO_WritePin(D3_GPIO_Port, D3_Pin, y.b3);
	HAL_GPIO_WritePin(D4_GPIO_Port, D4_Pin, y.b4);
	HAL_GPIO_WritePin(D5_GPIO_Port, D5_Pin, y.b5);
	HAL_GPIO_WritePin(D6_GPIO_Port, D6_Pin, y.b6);
	HAL_GPIO_WritePin(D7_GPIO_Port, D7_Pin, y.b7);
}
void GLCD_WriteCommand(uint8_t cmd)
{
	HAL_GPIO_WritePin(RS_GPIO_Port, RS_Pin, 0);
	HAL_GPIO_WritePin(RW_GPIO_Port, RW_Pin, 0);

	Data_Write(cmd);

	HAL_GPIO_WritePin(EN_GPIO_Port, EN_Pin, 1);
	HAL_Delay(1);
	HAL_GPIO_WritePin(EN_GPIO_Port, EN_Pin, 0);
	HAL_Delay(1);
}
void GLCD_WriteData(uint8_t data)
{
	HAL_GPIO_WritePin(RS_GPIO_Port, RS_Pin, 1);
	HAL_GPIO_WritePin(RW_GPIO_Port, RW_Pin, 0);

	Data_Write(data);

	HAL_GPIO_WritePin(EN_GPIO_Port, EN_Pin, 1);
	HAL_Delay(1);
	HAL_GPIO_WritePin(EN_GPIO_Port, EN_Pin, 0);
	HAL_Delay(1);
}
void GLCD_Initialize( void )
{
	HAL_GPIO_WritePin(RST_GPIO_Port, RST_Pin, 0);
	HAL_Delay(2);
	HAL_GPIO_WritePin(RST_GPIO_Port, RST_Pin, 1);
	HAL_Delay(1);
	GLCD_PageSelect(2);
	HAL_Delay(1);
	GLCD_WriteCommand(0x0C);
	GLCD_WriteCommand(0x3F);
	HAL_Delay(1);
	GLCD_PageSelect(3);
	HAL_Delay(1);

}
void GLCD_PageSelect(uint8_t page_select){

	switch(page_select)
	{
	case 0:
		HAL_GPIO_WritePin(CS1_GPIO_Port, CS1_Pin, 1);
		HAL_GPIO_WritePin(CS2_GPIO_Port, CS1_Pin, 0);
	break;
	case 1:
		HAL_GPIO_WritePin(CS1_GPIO_Port, CS1_Pin, 0);
		HAL_GPIO_WritePin(CS2_GPIO_Port, CS1_Pin, 1);
	break;
	case 2:
		HAL_GPIO_WritePin(CS1_GPIO_Port, CS1_Pin, 1);
		HAL_GPIO_WritePin(CS2_GPIO_Port, CS1_Pin, 1);
	break;
	case 3:
		HAL_GPIO_WritePin(CS1_GPIO_Port, CS1_Pin, 0);
		HAL_GPIO_WritePin(CS2_GPIO_Port, CS1_Pin, 0);
	break;
	default:

		HAL_GPIO_WritePin(CS1_GPIO_Port, CS1_Pin, 1);
		HAL_GPIO_WritePin(CS1_GPIO_Port, CS1_Pin, 0);
	break;
	}
}
void GLCD_PrintChar(const char *ptr)
{
	uint8_t i=0;
	GLCD_PageSelect(1);
	for(i=0;i<5;i++){

		GLCD_WriteData(ptr[i]);
	}
}
void GLCD_SetCursor(uint8_t x, uint8_t y)
{

	GLCD_WriteCommand(0xB8 + x);
	GLCD_WriteCommand(0x40 + y);
}

void GLCD_CreateImage(const char *image){
    unsigned int i=0,j=0;
    int page[]={0xB8,0xB9,0xBA,0xBB,0xBC,0xBD,0xBE,0xBF};

    HAL_Delay(1);
    GLCD_WriteCommand(0xC0);    //Start line, (64 rows) selects from where to start(1 line)
    for(i=0;i<=7;i++){
        GLCD_PageSelect(0);
        GLCD_WriteCommand(page[i]);
        GLCD_WriteCommand(0x40);    //Setting y-address
        for(j=0+(i*128);j<=63+(i*128);j++){
            GLCD_WriteData(image[j]);
        }
        GLCD_PageSelect(1);
        GLCD_WriteCommand(page[i]);
        GLCD_WriteCommand(0x40);    //Setting y-address
        for(j=64+(i*128);j<=127+(i*128);j++){
        	GLCD_WriteData(image[j]);
        }
        j=0;
    }
}

void GLCD_WriteString(const char *str){
    int i = 0;
    int startfont=0,endfont=0;
    while(*str != '\0'){
        startfont = (*str-32)*5;
        endfont = startfont + 5 ;
        for(i=startfont;i<endfont;i++){
            GLCD_WriteData(sys5x7[i]);
            HAL_Delay(1);
        }
        *str++;
    }

}

void GLCD_ClearAll( void )		/* GLCD all display clear function */
{
	int i,j;
	GLCD_PageSelect(2);	/* Select left & right half of display */
	for(i=0;i<8;i++)
	{
		GLCD_WriteCommand((0xB8)+i);	/* Increment page */
		for(j=0;j<64;j++)
		{
			GLCD_WriteData(0);	/* Write zeros to all 64 column */
		}
	}
	GLCD_WriteCommand(0x40);	/* Set Y address (column=0) */
	GLCD_WriteCommand(0xB8);	/* Set x address (page=0) */
}

/* USER CODE END 4 */

void Error_Handler(void)
{
  __disable_irq();
  while (1)
  {
  }
}
